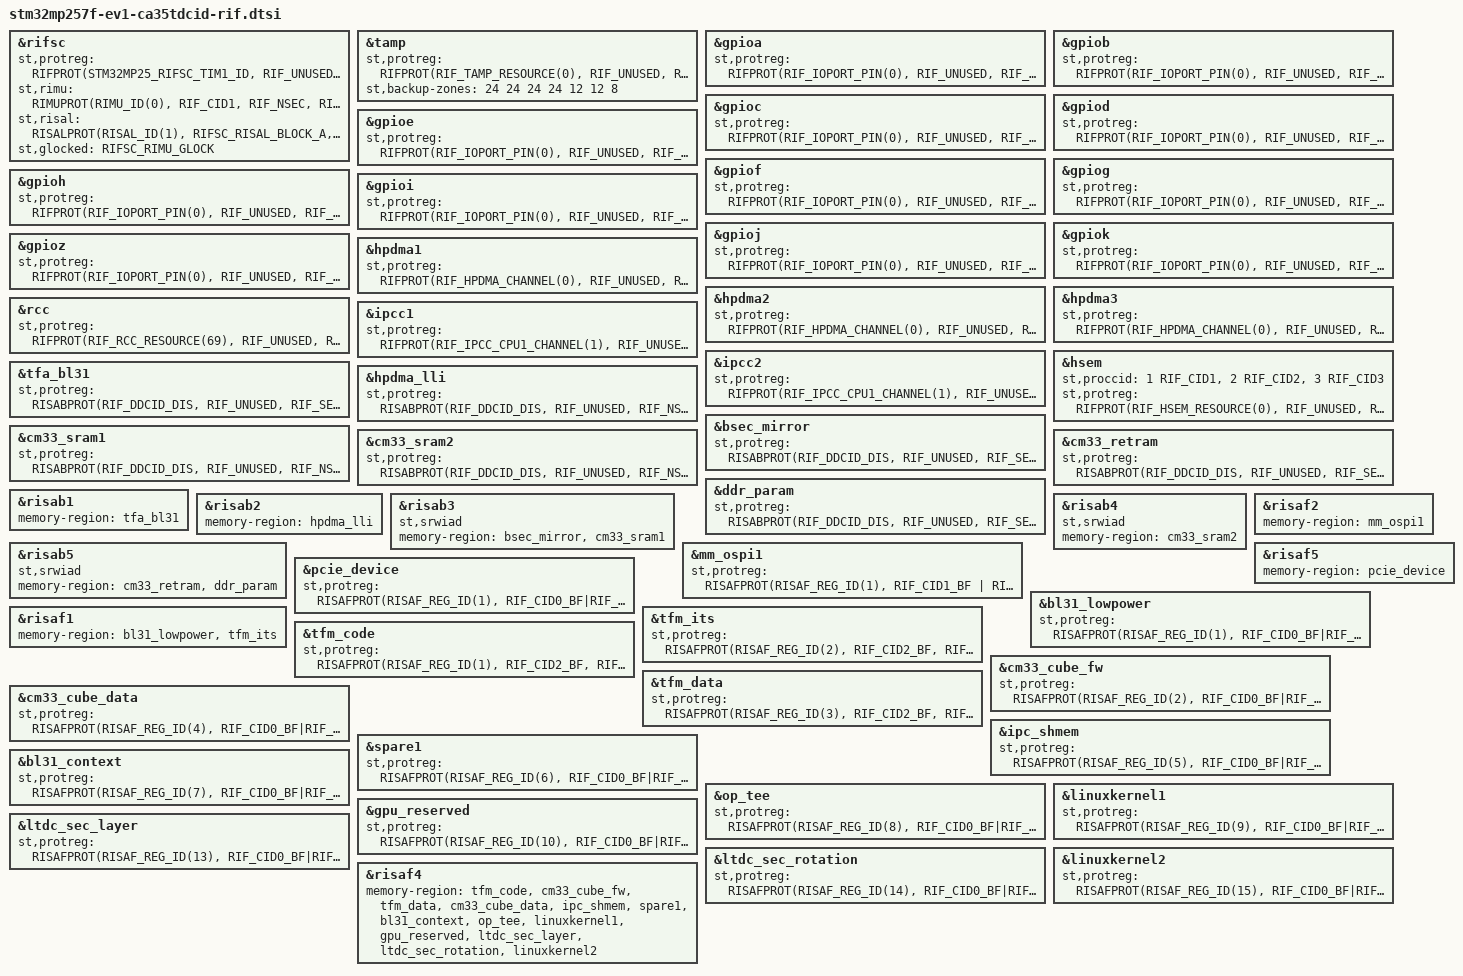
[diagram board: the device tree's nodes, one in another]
// SPDX-License-Identifier: (GPL-2.0-or-later OR BSD-3-Clause)
/*
 * Copyright (C) STMicroelectronics 2024 - All Rights Reserved
 */

/* Break alphabetical to group RIF configuration by feature to ease DT readability */

&rifsc {
	st,protreg = <
		RIFPROT(STM32MP25_RIFSC_TIM1_ID, RIF_UNUSED, RIF_UNLOCK, RIF_NSEC, RIF_NPRIV, RIF_UNUSED, RIF_SEM_DIS, RIF_CFDIS)
		RIFPROT(STM32MP25_RIFSC_TIM2_ID, RIF_UNUSED, RIF_UNLOCK, RIF_NSEC, RIF_NPRIV, RIF_UNUSED, RIF_SEM_DIS, RIF_CFDIS)
		RIFPROT(STM32MP25_RIFSC_TIM3_ID, RIF_UNUSED, RIF_UNLOCK, RIF_NSEC, RIF_NPRIV, RIF_UNUSED, RIF_SEM_DIS, RIF_CFDIS)
		RIFPROT(STM32MP25_RIFSC_TIM4_ID, RIF_UNUSED, RIF_UNLOCK, RIF_NSEC, RIF_NPRIV, RIF_UNUSED, RIF_SEM_DIS, RIF_CFDIS)
		RIFPROT(STM32MP25_RIFSC_TIM5_ID, RIF_UNUSED, RIF_UNLOCK, RIF_NSEC, RIF_NPRIV, RIF_UNUSED, RIF_SEM_DIS, RIF_CFDIS)
		RIFPROT(STM32MP25_RIFSC_TIM6_ID, RIF_UNUSED, RIF_UNLOCK, RIF_NSEC, RIF_NPRIV, RIF_UNUSED, RIF_SEM_DIS, RIF_CFDIS)
		RIFPROT(STM32MP25_RIFSC_TIM7_ID, RIF_UNUSED, RIF_UNLOCK, RIF_NSEC, RIF_NPRIV, RIF_UNUSED, RIF_SEM_DIS, RIF_CFDIS)
		RIFPROT(STM32MP25_RIFSC_TIM8_ID, RIF_UNUSED, RIF_UNLOCK, RIF_NSEC, RIF_NPRIV, RIF_UNUSED, RIF_SEM_DIS, RIF_CFDIS)
		RIFPROT(STM32MP25_RIFSC_TIM10_ID, RIF_UNUSED, RIF_UNLOCK, RIF_NSEC, RIF_NPRIV, RIF_UNUSED, RIF_SEM_DIS, RIF_CFDIS)
		RIFPROT(STM32MP25_RIFSC_TIM11_ID, RIF_UNUSED, RIF_UNLOCK, RIF_NSEC, RIF_NPRIV, RIF_UNUSED, RIF_SEM_DIS, RIF_CFDIS)
		RIFPROT(STM32MP25_RIFSC_TIM12_ID, RIF_UNUSED, RIF_UNLOCK, RIF_NSEC, RIF_NPRIV, RIF_UNUSED, RIF_SEM_DIS, RIF_CFDIS)
		RIFPROT(STM32MP25_RIFSC_TIM13_ID, RIF_UNUSED, RIF_UNLOCK, RIF_NSEC, RIF_NPRIV, RIF_UNUSED, RIF_SEM_DIS, RIF_CFDIS)
		RIFPROT(STM32MP25_RIFSC_TIM14_ID, RIF_UNUSED, RIF_UNLOCK, RIF_NSEC, RIF_NPRIV, RIF_UNUSED, RIF_SEM_DIS, RIF_CFDIS)
		RIFPROT(STM32MP25_RIFSC_TIM15_ID, RIF_UNUSED, RIF_UNLOCK, RIF_NSEC, RIF_NPRIV, RIF_UNUSED, RIF_SEM_DIS, RIF_CFDIS)
		RIFPROT(STM32MP25_RIFSC_TIM16_ID, RIF_UNUSED, RIF_UNLOCK, RIF_NSEC, RIF_NPRIV, RIF_UNUSED, RIF_SEM_DIS, RIF_CFDIS)
		RIFPROT(STM32MP25_RIFSC_TIM17_ID, RIF_UNUSED, RIF_UNLOCK, RIF_NSEC, RIF_NPRIV, RIF_UNUSED, RIF_SEM_DIS, RIF_CFDIS)
		RIFPROT(STM32MP25_RIFSC_TIM20_ID, RIF_UNUSED, RIF_UNLOCK, RIF_NSEC, RIF_NPRIV, RIF_UNUSED, RIF_SEM_DIS, RIF_CFDIS)
		RIFPROT(STM32MP25_RIFSC_LPTIM1_ID, RIF_UNUSED, RIF_UNLOCK, RIF_SEC, RIF_PRIV, RIF_CID1, RIF_SEM_DIS, RIF_CFEN)
		RIFPROT(STM32MP25_RIFSC_LPTIM2_ID, RIF_UNUSED, RIF_UNLOCK, RIF_NSEC, RIF_NPRIV, RIF_UNUSED, RIF_SEM_DIS, RIF_CFDIS)
		RIFPROT(STM32MP25_RIFSC_LPTIM3_ID, RIF_UNUSED, RIF_UNLOCK, RIF_NSEC, RIF_NPRIV, RIF_UNUSED, RIF_SEM_DIS, RIF_CFDIS)
		RIFPROT(STM32MP25_RIFSC_LPTIM4_ID, RIF_UNUSED, RIF_UNLOCK, RIF_NSEC, RIF_NPRIV, RIF_UNUSED, RIF_SEM_DIS, RIF_CFDIS)
		RIFPROT(STM32MP25_RIFSC_LPTIM5_ID, RIF_UNUSED, RIF_UNLOCK, RIF_NSEC, RIF_NPRIV, RIF_UNUSED, RIF_SEM_DIS, RIF_CFDIS)
		RIFPROT(STM32MP25_RIFSC_SPI1_ID, RIF_UNUSED, RIF_UNLOCK, RIF_NSEC, RIF_NPRIV, RIF_UNUSED, RIF_SEM_DIS, RIF_CFDIS)
		RIFPROT(STM32MP25_RIFSC_SPI2_ID, RIF_UNUSED, RIF_UNLOCK, RIF_NSEC, RIF_NPRIV, RIF_UNUSED, RIF_SEM_DIS, RIF_CFDIS)
		RIFPROT(STM32MP25_RIFSC_SPI3_ID, RIF_UNUSED, RIF_UNLOCK, RIF_NSEC, RIF_NPRIV, RIF_UNUSED, RIF_SEM_DIS, RIF_CFDIS)
		RIFPROT(STM32MP25_RIFSC_SPI4_ID, RIF_UNUSED, RIF_UNLOCK, RIF_NSEC, RIF_NPRIV, RIF_UNUSED, RIF_SEM_DIS, RIF_CFDIS)
		RIFPROT(STM32MP25_RIFSC_SPI5_ID, RIF_UNUSED, RIF_UNLOCK, RIF_NSEC, RIF_NPRIV, RIF_UNUSED, RIF_SEM_DIS, RIF_CFDIS)
		RIFPROT(STM32MP25_RIFSC_SPI6_ID, RIF_UNUSED, RIF_UNLOCK, RIF_NSEC, RIF_NPRIV, RIF_UNUSED, RIF_SEM_DIS, RIF_CFDIS)
		RIFPROT(STM32MP25_RIFSC_SPI7_ID, RIF_UNUSED, RIF_UNLOCK, RIF_NSEC, RIF_NPRIV, RIF_UNUSED, RIF_SEM_DIS, RIF_CFDIS)
		RIFPROT(STM32MP25_RIFSC_SPI8_ID, RIF_UNUSED, RIF_UNLOCK, RIF_NSEC, RIF_NPRIV, RIF_UNUSED, RIF_SEM_DIS, RIF_CFDIS)
		RIFPROT(STM32MP25_RIFSC_SPDIFRX_ID, RIF_UNUSED, RIF_UNLOCK, RIF_NSEC, RIF_NPRIV, RIF_UNUSED, RIF_SEM_DIS, RIF_CFDIS)
		RIFPROT(STM32MP25_RIFSC_USART1_ID, RIF_UNUSED, RIF_UNLOCK, RIF_NSEC, RIF_NPRIV, RIF_UNUSED, RIF_SEM_DIS, RIF_CFDIS)
		RIFPROT(STM32MP25_RIFSC_USART2_ID, RIF_UNUSED, RIF_UNLOCK, RIF_NSEC, RIF_NPRIV, RIF_UNUSED, RIF_SEM_DIS, RIF_CFDIS)
		RIFPROT(STM32MP25_RIFSC_USART3_ID, RIF_UNUSED, RIF_UNLOCK, RIF_NSEC, RIF_NPRIV, RIF_UNUSED, RIF_SEM_DIS, RIF_CFDIS)
		RIFPROT(STM32MP25_RIFSC_UART4_ID, RIF_UNUSED, RIF_UNLOCK, RIF_NSEC, RIF_NPRIV, RIF_UNUSED, RIF_SEM_DIS, RIF_CFDIS)
		RIFPROT(STM32MP25_RIFSC_UART5_ID, RIF_UNUSED, RIF_UNLOCK, RIF_NSEC, RIF_NPRIV, RIF_UNUSED, RIF_SEM_DIS, RIF_CFDIS)
		RIFPROT(STM32MP25_RIFSC_USART6_ID, RIF_UNUSED, RIF_UNLOCK, RIF_NSEC, RIF_NPRIV, RIF_UNUSED, RIF_SEM_DIS, RIF_CFDIS)
		RIFPROT(STM32MP25_RIFSC_UART7_ID, RIF_UNUSED, RIF_UNLOCK, RIF_NSEC, RIF_NPRIV, RIF_UNUSED, RIF_SEM_DIS, RIF_CFDIS)
		RIFPROT(STM32MP25_RIFSC_UART8_ID, RIF_UNUSED, RIF_UNLOCK, RIF_NSEC, RIF_NPRIV, RIF_UNUSED, RIF_SEM_DIS, RIF_CFDIS)
		RIFPROT(STM32MP25_RIFSC_UART9_ID, RIF_UNUSED, RIF_UNLOCK, RIF_NSEC, RIF_NPRIV, RIF_UNUSED, RIF_SEM_DIS, RIF_CFDIS)
		RIFPROT(STM32MP25_RIFSC_LPUART1_ID, RIF_UNUSED, RIF_UNLOCK, RIF_NSEC, RIF_NPRIV, RIF_UNUSED, RIF_SEM_DIS, RIF_CFDIS)
		RIFPROT(STM32MP25_RIFSC_I2C1_ID, RIF_UNUSED, RIF_UNLOCK, RIF_NSEC, RIF_NPRIV, RIF_UNUSED, RIF_SEM_DIS, RIF_CFDIS)
		RIFPROT(STM32MP25_RIFSC_I2C2_ID, RIF_UNUSED, RIF_UNLOCK, RIF_NSEC, RIF_NPRIV, RIF_UNUSED, RIF_SEM_DIS, RIF_CFDIS)
		RIFPROT(STM32MP25_RIFSC_I2C3_ID, RIF_UNUSED, RIF_UNLOCK, RIF_NSEC, RIF_NPRIV, RIF_UNUSED, RIF_SEM_DIS, RIF_CFDIS)
		RIFPROT(STM32MP25_RIFSC_I2C4_ID, RIF_UNUSED, RIF_UNLOCK, RIF_NSEC, RIF_NPRIV, RIF_UNUSED, RIF_SEM_DIS, RIF_CFDIS)
		RIFPROT(STM32MP25_RIFSC_I2C5_ID, RIF_UNUSED, RIF_UNLOCK, RIF_NSEC, RIF_NPRIV, RIF_UNUSED, RIF_SEM_DIS, RIF_CFDIS)
		RIFPROT(STM32MP25_RIFSC_I2C6_ID, RIF_UNUSED, RIF_UNLOCK, RIF_NSEC, RIF_NPRIV, RIF_UNUSED, RIF_SEM_DIS, RIF_CFDIS)
		RIFPROT(STM32MP25_RIFSC_I2C7_ID, RIF_UNUSED, RIF_UNLOCK, RIF_SEC, RIF_PRIV, RIF_CID1, RIF_SEM_DIS, RIF_CFEN)
		RIFPROT(STM32MP25_RIFSC_I2C8_ID, RIF_UNUSED, RIF_UNLOCK, RIF_NSEC, RIF_NPRIV, RIF_UNUSED, RIF_SEM_DIS, RIF_CFDIS)
		RIFPROT(STM32MP25_RIFSC_SAI1_ID, RIF_UNUSED, RIF_UNLOCK, RIF_NSEC, RIF_NPRIV, RIF_UNUSED, RIF_SEM_DIS, RIF_CFDIS)
		RIFPROT(STM32MP25_RIFSC_SAI2_ID, RIF_UNUSED, RIF_UNLOCK, RIF_NSEC, RIF_NPRIV, RIF_UNUSED, RIF_SEM_DIS, RIF_CFDIS)
		RIFPROT(STM32MP25_RIFSC_SAI3_ID, RIF_UNUSED, RIF_UNLOCK, RIF_NSEC, RIF_NPRIV, RIF_UNUSED, RIF_SEM_DIS, RIF_CFDIS)
		RIFPROT(STM32MP25_RIFSC_SAI4_ID, RIF_UNUSED, RIF_UNLOCK, RIF_NSEC, RIF_NPRIV, RIF_UNUSED, RIF_SEM_DIS, RIF_CFDIS)
		RIFPROT(STM32MP25_RIFSC_MDF1_ID, RIF_UNUSED, RIF_UNLOCK, RIF_NSEC, RIF_NPRIV, RIF_UNUSED, RIF_SEM_DIS, RIF_CFDIS)
		RIFPROT(STM32MP25_RIFSC_ADF1_ID, RIF_UNUSED, RIF_UNLOCK, RIF_NSEC, RIF_NPRIV, RIF_UNUSED, RIF_SEM_DIS, RIF_CFDIS)
		RIFPROT(STM32MP25_RIFSC_FDCAN_ID, RIF_UNUSED, RIF_UNLOCK, RIF_NSEC, RIF_NPRIV, RIF_UNUSED, RIF_SEM_DIS, RIF_CFDIS)
		RIFPROT(STM32MP25_RIFSC_HDP_ID, RIF_UNUSED, RIF_UNLOCK, RIF_NSEC, RIF_NPRIV, RIF_UNUSED, RIF_SEM_DIS, RIF_CFDIS)
		RIFPROT(STM32MP25_RIFSC_ADC12_ID, RIF_UNUSED, RIF_UNLOCK, RIF_NSEC, RIF_NPRIV, RIF_UNUSED, RIF_SEM_DIS, RIF_CFDIS)
		RIFPROT(STM32MP25_RIFSC_ADC3_ID, RIF_UNUSED, RIF_UNLOCK, RIF_NSEC, RIF_NPRIV, RIF_UNUSED, RIF_SEM_DIS, RIF_CFDIS)
		RIFPROT(STM32MP25_RIFSC_ETH1_ID, RIF_UNUSED, RIF_UNLOCK, RIF_NSEC, RIF_NPRIV, RIF_UNUSED, RIF_SEM_DIS, RIF_CFDIS)
		RIFPROT(STM32MP25_RIFSC_ETH2_ID, RIF_UNUSED, RIF_UNLOCK, RIF_NSEC, RIF_NPRIV, RIF_UNUSED, RIF_SEM_DIS, RIF_CFDIS)
		RIFPROT(STM32MP25_RIFSC_ETHSW_DEIP_ID, RIF_UNUSED, RIF_UNLOCK, RIF_NSEC, RIF_NPRIV, RIF_UNUSED, RIF_SEM_DIS, RIF_CFDIS)
		RIFPROT(STM32MP25_RIFSC_ETHSW_ACM_MSGBUF_ID, RIF_UNUSED, RIF_UNLOCK, RIF_NSEC, RIF_NPRIV, RIF_UNUSED, RIF_SEM_DIS, RIF_CFDIS)
		RIFPROT(STM32MP25_RIFSC_ETHSW_ACM_CFG_ID, RIF_UNUSED, RIF_UNLOCK, RIF_NSEC, RIF_NPRIV, RIF_UNUSED, RIF_SEM_DIS, RIF_CFDIS)
		RIFPROT(STM32MP25_RIFSC_USBH_ID, RIF_UNUSED, RIF_UNLOCK, RIF_NSEC, RIF_NPRIV, RIF_UNUSED, RIF_SEM_DIS, RIF_CFDIS)
		RIFPROT(STM32MP25_RIFSC_USB3DR_ID, RIF_UNUSED, RIF_UNLOCK, RIF_NSEC, RIF_NPRIV, RIF_UNUSED, RIF_SEM_DIS, RIF_CFDIS)
		RIFPROT(STM32MP25_RIFSC_COMBOPHY_ID, RIF_UNUSED, RIF_UNLOCK, RIF_NSEC, RIF_NPRIV, RIF_UNUSED, RIF_SEM_DIS, RIF_CFDIS)
		RIFPROT(STM32MP25_RIFSC_PCIE_ID, RIF_UNUSED, RIF_UNLOCK, RIF_NSEC, RIF_NPRIV, RIF_UNUSED, RIF_SEM_DIS, RIF_CFDIS)
		RIFPROT(STM32MP25_RIFSC_UCPD1_ID, RIF_UNUSED, RIF_UNLOCK, RIF_NSEC, RIF_NPRIV, RIF_UNUSED, RIF_SEM_DIS, RIF_CFDIS)
		RIFPROT(STM32MP25_RIFSC_STGEN_ID, RIF_UNUSED, RIF_LOCK, RIF_SEC, RIF_PRIV, RIF_CID1, RIF_SEM_DIS, RIF_CFEN)
		RIFPROT(STM32MP25_RIFSC_SDMMC1_ID, RIF_UNUSED, RIF_UNLOCK, RIF_NSEC, RIF_NPRIV, RIF_UNUSED, RIF_SEM_DIS, RIF_CFDIS)
		RIFPROT(STM32MP25_RIFSC_SDMMC2_ID, RIF_UNUSED, RIF_UNLOCK, RIF_NSEC, RIF_NPRIV, RIF_UNUSED, RIF_SEM_DIS, RIF_CFDIS)
		RIFPROT(STM32MP25_RIFSC_SDMMC3_ID, RIF_UNUSED, RIF_UNLOCK, RIF_NSEC, RIF_NPRIV, RIF_UNUSED, RIF_SEM_DIS, RIF_CFDIS)
		RIFPROT(STM32MP25_RIFSC_GPU_ID, RIF_UNUSED, RIF_UNLOCK, RIF_NSEC, RIF_NPRIV, RIF_UNUSED, RIF_SEM_DIS, RIF_CFDIS)
		RIFPROT(STM32MP25_RIFSC_LTDC_CMN_ID, RIF_UNUSED, RIF_UNLOCK, RIF_NSEC, RIF_NPRIV, RIF_UNUSED, RIF_SEM_DIS, RIF_CFDIS)
		RIFPROT(STM32MP25_RIFSC_LTDC_L0L1_ID, RIF_UNUSED, RIF_UNLOCK, RIF_NSEC, RIF_NPRIV, RIF_UNUSED, RIF_SEM_DIS, RIF_CFDIS)
		RIFPROT(STM32MP25_RIFSC_LTDC_L2_ID, RIF_UNUSED, RIF_UNLOCK, RIF_NSEC, RIF_NPRIV, RIF_UNUSED, RIF_SEM_DIS, RIF_CFDIS)
		RIFPROT(STM32MP25_RIFSC_LTDC_ROT_ID, RIF_UNUSED, RIF_UNLOCK, RIF_NSEC, RIF_NPRIV, RIF_UNUSED, RIF_SEM_DIS, RIF_CFDIS)
		RIFPROT(STM32MP25_RIFSC_DSI_CMN_ID, RIF_UNUSED, RIF_UNLOCK, RIF_NSEC, RIF_NPRIV, RIF_UNUSED, RIF_SEM_DIS, RIF_CFDIS)
		RIFPROT(STM32MP25_RIFSC_DSI_TRIG_ID, RIF_UNUSED, RIF_UNLOCK, RIF_NSEC, RIF_NPRIV, RIF_UNUSED, RIF_SEM_DIS, RIF_CFDIS)
		RIFPROT(STM32MP25_RIFSC_DSI_RDFIFO_ID, RIF_UNUSED, RIF_UNLOCK, RIF_NSEC, RIF_NPRIV, RIF_UNUSED, RIF_SEM_DIS, RIF_CFDIS)
		RIFPROT(STM32MP25_RIFSC_LVDS_ID, RIF_UNUSED, RIF_UNLOCK, RIF_NSEC, RIF_NPRIV, RIF_UNUSED, RIF_SEM_DIS, RIF_CFDIS)
		RIFPROT(STM32MP25_RIFSC_CSI_ID, RIF_UNUSED, RIF_UNLOCK, RIF_NSEC, RIF_NPRIV, RIF_UNUSED, RIF_SEM_DIS, RIF_CFDIS)
		RIFPROT(STM32MP25_RIFSC_DCMIPP_ID, RIF_UNUSED, RIF_UNLOCK, RIF_NSEC, RIF_NPRIV, RIF_UNUSED, RIF_SEM_DIS, RIF_CFDIS)
		RIFPROT(STM32MP25_RIFSC_DCMI_PSSI_ID, RIF_UNUSED, RIF_UNLOCK, RIF_NSEC, RIF_NPRIV, RIF_UNUSED, RIF_SEM_DIS, RIF_CFDIS)
		RIFPROT(STM32MP25_RIFSC_VDEC_ID, RIF_UNUSED, RIF_UNLOCK, RIF_NSEC, RIF_NPRIV, RIF_UNUSED, RIF_SEM_DIS, RIF_CFDIS)
		RIFPROT(STM32MP25_RIFSC_VENC_ID, RIF_UNUSED, RIF_UNLOCK, RIF_NSEC, RIF_NPRIV, RIF_UNUSED, RIF_SEM_DIS, RIF_CFDIS)
		RIFPROT(STM32MP25_RIFSC_RNG_ID, RIF_UNUSED, RIF_LOCK, RIF_SEC, RIF_PRIV, RIF_CID1, RIF_SEM_DIS, RIF_CFEN)
		RIFPROT(STM32MP25_RIFSC_PKA_ID, RIF_UNUSED, RIF_LOCK, RIF_SEC, RIF_PRIV, RIF_CID1, RIF_SEM_DIS, RIF_CFEN)
		RIFPROT(STM32MP25_RIFSC_SAES_ID, RIF_UNUSED, RIF_LOCK, RIF_SEC, RIF_PRIV, RIF_CID1, RIF_SEM_DIS, RIF_CFEN)
		RIFPROT(STM32MP25_RIFSC_HASH_ID, RIF_UNUSED, RIF_LOCK, RIF_SEC, RIF_PRIV, RIF_CID1, RIF_SEM_DIS, RIF_CFEN)
		RIFPROT(STM32MP25_RIFSC_CRYP1_ID, RIF_UNUSED, RIF_UNLOCK, RIF_NSEC, RIF_NPRIV, RIF_UNUSED, RIF_SEM_DIS, RIF_CFDIS)
		RIFPROT(STM32MP25_RIFSC_CRYP2_ID, RIF_UNUSED, RIF_UNLOCK, RIF_SEC, RIF_PRIV, RIF_CID2, RIF_SEM_DIS, RIF_CFEN)
		RIFPROT(STM32MP25_RIFSC_IWDG1_ID, RIF_UNUSED, RIF_LOCK, RIF_SEC, RIF_PRIV, RIF_CID1, RIF_SEM_DIS, RIF_CFEN)
		RIFPROT(STM32MP25_RIFSC_IWDG2_ID, RIF_UNUSED, RIF_UNLOCK, RIF_NSEC, RIF_NPRIV, RIF_UNUSED, RIF_SEM_DIS, RIF_CFDIS)
		RIFPROT(STM32MP25_RIFSC_IWDG3_ID, RIF_UNUSED, RIF_UNLOCK, RIF_SEC, RIF_PRIV, RIF_CID2, RIF_SEM_DIS, RIF_CFEN)
		RIFPROT(STM32MP25_RIFSC_IWDG4_ID, RIF_UNUSED, RIF_UNLOCK, RIF_NSEC, RIF_NPRIV, RIF_UNUSED, RIF_SEM_DIS, RIF_CFDIS)
		RIFPROT(STM32MP25_RIFSC_IWDG5_ID, RIF_UNUSED, RIF_UNLOCK, RIF_NSEC, RIF_NPRIV, RIF_UNUSED, RIF_SEM_DIS, RIF_CFDIS)
		RIFPROT(STM32MP25_RIFSC_WWDG1_ID, RIF_UNUSED, RIF_UNLOCK, RIF_NSEC, RIF_NPRIV, RIF_UNUSED, RIF_SEM_DIS, RIF_CFDIS)
		RIFPROT(STM32MP25_RIFSC_WWDG2_ID, RIF_UNUSED, RIF_UNLOCK, RIF_NSEC, RIF_NPRIV, RIF_UNUSED, RIF_SEM_DIS, RIF_CFDIS)
		RIFPROT(STM32MP25_RIFSC_VREFBUF_ID, RIF_UNUSED, RIF_UNLOCK, RIF_SEC, RIF_PRIV, RIF_CID1, RIF_SEM_DIS, RIF_CFEN)
		RIFPROT(STM32MP25_RIFSC_DTS_ID, RIF_UNUSED, RIF_UNLOCK, RIF_NSEC, RIF_NPRIV, RIF_UNUSED, RIF_SEM_DIS, RIF_CFDIS)
		RIFPROT(STM32MP25_RIFSC_RAMCFG_ID, RIF_UNUSED, RIF_UNLOCK, RIF_SEC, RIF_PRIV, RIF_CID1, RIF_SEM_DIS, RIF_CFEN)
		RIFPROT(STM32MP25_RIFSC_CRC_ID, RIF_UNUSED, RIF_UNLOCK, RIF_NSEC, RIF_NPRIV, RIF_UNUSED, RIF_SEM_DIS, RIF_CFDIS)
		RIFPROT(STM32MP25_RIFSC_SERC_ID, RIF_UNUSED, RIF_UNLOCK, RIF_SEC, RIF_PRIV, RIF_CID1, RIF_SEM_DIS, RIF_CFEN)
		RIFPROT(STM32MP25_RIFSC_GICV2M_ID, RIF_UNUSED, RIF_UNLOCK, RIF_NSEC, RIF_NPRIV, RIF_UNUSED, RIF_SEM_DIS, RIF_CFDIS)
		RIFPROT(STM32MP25_RIFSC_I3C1_ID, RIF_UNUSED, RIF_UNLOCK, RIF_NSEC, RIF_NPRIV, RIF_UNUSED, RIF_SEM_DIS, RIF_CFDIS)
		RIFPROT(STM32MP25_RIFSC_I3C2_ID, RIF_UNUSED, RIF_UNLOCK, RIF_NSEC, RIF_NPRIV, RIF_UNUSED, RIF_SEM_DIS, RIF_CFDIS)
		RIFPROT(STM32MP25_RIFSC_I3C3_ID, RIF_UNUSED, RIF_UNLOCK, RIF_NSEC, RIF_NPRIV, RIF_UNUSED, RIF_SEM_DIS, RIF_CFDIS)
		RIFPROT(STM32MP25_RIFSC_I3C4_ID, RIF_UNUSED, RIF_UNLOCK, RIF_NSEC, RIF_NPRIV, RIF_UNUSED, RIF_SEM_DIS, RIF_CFDIS)
		RIFPROT(STM32MP25_RIFSC_ICACHE_DCACHE_ID, RIF_UNUSED, RIF_UNLOCK, RIF_NSEC, RIF_NPRIV, RIF_UNUSED, RIF_SEM_DIS, RIF_CFDIS)
	>;
	st,rimu = <
		RIMUPROT(RIMU_ID(0), RIF_CID1, RIF_NSEC, RIF_PRIV, RIF_CIDSEL_M)
		RIMUPROT(RIMU_ID(1), RIF_UNUSED, RIF_NSEC, RIF_PRIV, RIF_CIDSEL_P)
		RIMUPROT(RIMU_ID(2), RIF_UNUSED, RIF_NSEC, RIF_PRIV, RIF_CIDSEL_P)
		RIMUPROT(RIMU_ID(3), RIF_UNUSED, RIF_NSEC, RIF_PRIV, RIF_CIDSEL_P)
		RIMUPROT(RIMU_ID(4), RIF_UNUSED, RIF_NSEC, RIF_PRIV, RIF_CIDSEL_P)
		RIMUPROT(RIMU_ID(5), RIF_UNUSED, RIF_NSEC, RIF_PRIV, RIF_CIDSEL_P)
		RIMUPROT(RIMU_ID(6), RIF_UNUSED, RIF_NSEC, RIF_PRIV, RIF_CIDSEL_P)
		RIMUPROT(RIMU_ID(7), RIF_UNUSED, RIF_NSEC, RIF_PRIV, RIF_CIDSEL_P)
		RIMUPROT(RIMU_ID(8), RIF_UNUSED, RIF_NSEC, RIF_PRIV, RIF_CIDSEL_P)
		RIMUPROT(RIMU_ID(9), RIF_UNUSED, RIF_NSEC, RIF_PRIV, RIF_CIDSEL_P)
		RIMUPROT(RIMU_ID(10), RIF_UNUSED, RIF_NSEC, RIF_PRIV, RIF_CIDSEL_P)
		RIMUPROT(RIMU_ID(11), RIF_CID0, RIF_NSEC, RIF_PRIV, RIF_CIDSEL_M)
		RIMUPROT(RIMU_ID(12), RIF_CID0, RIF_NSEC, RIF_PRIV, RIF_CIDSEL_M)
		RIMUPROT(RIMU_ID(13), RIF_CID0, RIF_NSEC, RIF_PRIV, RIF_CIDSEL_M)
		RIMUPROT(RIMU_ID(14), RIF_UNUSED, RIF_NSEC, RIF_PRIV, RIF_CIDSEL_P)
		RIMUPROT(RIMU_ID(15), RIF_UNUSED, RIF_NSEC, RIF_PRIV, RIF_CIDSEL_P)
	>;
	st,risal = <
		RISALPROT(RISAL_ID(1), RIFSC_RISAL_BLOCK_A, RIF_CID1, RIF_UNLOCK, RIF_NSEC, RIF_NPRIV, RIFSC_RISAL_SREN)
		RISALPROT(RISAL_ID(2), RIFSC_RISAL_BLOCK_A, RIF_CID1, RIF_UNLOCK, RIF_NSEC, RIF_NPRIV, RIFSC_RISAL_SREN)
		RISALPROT(RISAL_ID(3), RIFSC_RISAL_BLOCK_A, RIF_CID1, RIF_UNLOCK, RIF_NSEC, RIF_NPRIV, RIFSC_RISAL_SREN)
		RISALPROT(RISAL_ID(1), RIFSC_RISAL_BLOCK_B, RIF_CID3, RIF_UNLOCK, RIF_NSEC, RIF_NPRIV, RIFSC_RISAL_SREN)
		RISALPROT(RISAL_ID(2), RIFSC_RISAL_BLOCK_B, RIF_CID3, RIF_UNLOCK, RIF_NSEC, RIF_NPRIV, RIFSC_RISAL_SREN)
		RISALPROT(RISAL_ID(3), RIFSC_RISAL_BLOCK_B, RIF_CID3, RIF_UNLOCK, RIF_NSEC, RIF_NPRIV, RIFSC_RISAL_SREN)
	>;
	st,glocked = <RIFSC_RIMU_GLOCK>;
};

&tamp {
	st,protreg = <
		RIFPROT(RIF_TAMP_RESOURCE(0), RIF_UNUSED, RIF_UNLOCK, RIF_SEC, RIF_PRIV, RIF_CID1, RIF_SEM_DIS, RIF_CFEN)
		RIFPROT(RIF_TAMP_RESOURCE(1), RIF_UNUSED, RIF_UNLOCK, RIF_SEC, RIF_PRIV, RIF_CID1, RIF_SEM_DIS, RIF_CFEN)
		RIFPROT(RIF_TAMP_RESOURCE(2), RIF_UNUSED, RIF_UNLOCK, RIF_SEC, RIF_PRIV, RIF_CID2, RIF_SEM_DIS, RIF_CFEN)
	>;
	st,backup-zones = <24 24 24 24 12 12 8>;
};

&gpioa {
	st,protreg = <
		RIFPROT(RIF_IOPORT_PIN(0), RIF_UNUSED, RIF_UNLOCK, RIF_SEC, RIF_PRIV, RIF_CID1, RIF_SEM_DIS, RIF_CFEN)
		RIFPROT(RIF_IOPORT_PIN(1), RIF_UNUSED, RIF_UNLOCK, RIF_NSEC, RIF_NPRIV, RIF_UNUSED, RIF_SEM_DIS, RIF_CFDIS)
		RIFPROT(RIF_IOPORT_PIN(2), RIF_UNUSED, RIF_UNLOCK, RIF_NSEC, RIF_NPRIV, RIF_UNUSED, RIF_SEM_DIS, RIF_CFDIS)
		RIFPROT(RIF_IOPORT_PIN(3), RIF_UNUSED, RIF_UNLOCK, RIF_NSEC, RIF_NPRIV, RIF_UNUSED, RIF_SEM_DIS, RIF_CFDIS)
		RIFPROT(RIF_IOPORT_PIN(4), RIF_UNUSED, RIF_UNLOCK, RIF_NSEC, RIF_NPRIV, RIF_UNUSED, RIF_SEM_DIS, RIF_CFDIS)
		RIFPROT(RIF_IOPORT_PIN(5), RIF_UNUSED, RIF_UNLOCK, RIF_NSEC, RIF_NPRIV, RIF_UNUSED, RIF_SEM_DIS, RIF_CFDIS)
		RIFPROT(RIF_IOPORT_PIN(6), RIF_UNUSED, RIF_UNLOCK, RIF_NSEC, RIF_NPRIV, RIF_UNUSED, RIF_SEM_DIS, RIF_CFDIS)
		RIFPROT(RIF_IOPORT_PIN(7), RIF_UNUSED, RIF_UNLOCK, RIF_NSEC, RIF_NPRIV, RIF_UNUSED, RIF_SEM_DIS, RIF_CFDIS)
		RIFPROT(RIF_IOPORT_PIN(8), RIF_UNUSED, RIF_UNLOCK, RIF_NSEC, RIF_NPRIV, RIF_UNUSED, RIF_SEM_DIS, RIF_CFDIS)
		RIFPROT(RIF_IOPORT_PIN(9), RIF_UNUSED, RIF_UNLOCK, RIF_NSEC, RIF_NPRIV, RIF_UNUSED, RIF_SEM_DIS, RIF_CFDIS)
		RIFPROT(RIF_IOPORT_PIN(10), RIF_UNUSED, RIF_UNLOCK, RIF_NSEC, RIF_NPRIV, RIF_UNUSED, RIF_SEM_DIS, RIF_CFDIS)
		RIFPROT(RIF_IOPORT_PIN(11), RIF_UNUSED, RIF_UNLOCK, RIF_NSEC, RIF_NPRIV, RIF_UNUSED, RIF_SEM_DIS, RIF_CFDIS)
		RIFPROT(RIF_IOPORT_PIN(12), RIF_UNUSED, RIF_UNLOCK, RIF_NSEC, RIF_NPRIV, RIF_UNUSED, RIF_SEM_DIS, RIF_CFDIS)
		RIFPROT(RIF_IOPORT_PIN(13), RIF_UNUSED, RIF_UNLOCK, RIF_NSEC, RIF_NPRIV, RIF_UNUSED, RIF_SEM_DIS, RIF_CFDIS)
		RIFPROT(RIF_IOPORT_PIN(14), RIF_UNUSED, RIF_UNLOCK, RIF_NSEC, RIF_NPRIV, RIF_UNUSED, RIF_SEM_DIS, RIF_CFDIS)
		RIFPROT(RIF_IOPORT_PIN(15), RIF_UNUSED, RIF_UNLOCK, RIF_NSEC, RIF_NPRIV, RIF_UNUSED, RIF_SEM_DIS, RIF_CFDIS)
	>;
};

&gpiob {
	st,protreg = <
		RIFPROT(RIF_IOPORT_PIN(0), RIF_UNUSED, RIF_UNLOCK, RIF_NSEC, RIF_NPRIV, RIF_UNUSED, RIF_SEM_DIS, RIF_CFDIS)
		RIFPROT(RIF_IOPORT_PIN(1), RIF_UNUSED, RIF_UNLOCK, RIF_NSEC, RIF_NPRIV, RIF_UNUSED, RIF_SEM_DIS, RIF_CFDIS)
		RIFPROT(RIF_IOPORT_PIN(2), RIF_UNUSED, RIF_UNLOCK, RIF_NSEC, RIF_NPRIV, RIF_UNUSED, RIF_SEM_DIS, RIF_CFDIS)
		RIFPROT(RIF_IOPORT_PIN(3), RIF_UNUSED, RIF_UNLOCK, RIF_NSEC, RIF_NPRIV, RIF_UNUSED, RIF_SEM_DIS, RIF_CFDIS)
		RIFPROT(RIF_IOPORT_PIN(4), RIF_UNUSED, RIF_UNLOCK, RIF_NSEC, RIF_NPRIV, RIF_UNUSED, RIF_SEM_DIS, RIF_CFDIS)
		RIFPROT(RIF_IOPORT_PIN(5), RIF_UNUSED, RIF_UNLOCK, RIF_NSEC, RIF_NPRIV, RIF_UNUSED, RIF_SEM_DIS, RIF_CFDIS)
		RIFPROT(RIF_IOPORT_PIN(6), RIF_UNUSED, RIF_UNLOCK, RIF_NSEC, RIF_NPRIV, RIF_UNUSED, RIF_SEM_DIS, RIF_CFDIS)
		RIFPROT(RIF_IOPORT_PIN(7), RIF_UNUSED, RIF_UNLOCK, RIF_NSEC, RIF_NPRIV, RIF_UNUSED, RIF_SEM_DIS, RIF_CFDIS)
		RIFPROT(RIF_IOPORT_PIN(8), RIF_UNUSED, RIF_UNLOCK, RIF_NSEC, RIF_NPRIV, RIF_UNUSED, RIF_SEM_DIS, RIF_CFDIS)
		RIFPROT(RIF_IOPORT_PIN(9), RIF_UNUSED, RIF_UNLOCK, RIF_NSEC, RIF_NPRIV, RIF_UNUSED, RIF_SEM_DIS, RIF_CFDIS)
		RIFPROT(RIF_IOPORT_PIN(10), RIF_UNUSED, RIF_UNLOCK, RIF_NSEC, RIF_NPRIV, RIF_UNUSED, RIF_SEM_DIS, RIF_CFDIS)
		RIFPROT(RIF_IOPORT_PIN(11), RIF_UNUSED, RIF_UNLOCK, RIF_NSEC, RIF_NPRIV, RIF_UNUSED, RIF_SEM_DIS, RIF_CFDIS)
		RIFPROT(RIF_IOPORT_PIN(12), RIF_UNUSED, RIF_UNLOCK, RIF_NSEC, RIF_NPRIV, RIF_UNUSED, RIF_SEM_DIS, RIF_CFDIS)
		RIFPROT(RIF_IOPORT_PIN(13), RIF_UNUSED, RIF_UNLOCK, RIF_NSEC, RIF_NPRIV, RIF_UNUSED, RIF_SEM_DIS, RIF_CFDIS)
		RIFPROT(RIF_IOPORT_PIN(14), RIF_UNUSED, RIF_UNLOCK, RIF_NSEC, RIF_NPRIV, RIF_UNUSED, RIF_SEM_DIS, RIF_CFDIS)
		RIFPROT(RIF_IOPORT_PIN(15), RIF_UNUSED, RIF_UNLOCK, RIF_NSEC, RIF_NPRIV, RIF_UNUSED, RIF_SEM_DIS, RIF_CFDIS)
	>;
};

&gpioc {
	st,protreg = <
		RIFPROT(RIF_IOPORT_PIN(0), RIF_UNUSED, RIF_UNLOCK, RIF_NSEC, RIF_NPRIV, RIF_UNUSED, RIF_SEM_DIS, RIF_CFDIS)
		RIFPROT(RIF_IOPORT_PIN(1), RIF_UNUSED, RIF_UNLOCK, RIF_NSEC, RIF_NPRIV, RIF_UNUSED, RIF_SEM_DIS, RIF_CFDIS)
		RIFPROT(RIF_IOPORT_PIN(2), RIF_UNUSED, RIF_UNLOCK, RIF_NSEC, RIF_NPRIV, RIF_UNUSED, RIF_SEM_DIS, RIF_CFDIS)
		RIFPROT(RIF_IOPORT_PIN(3), RIF_UNUSED, RIF_UNLOCK, RIF_NSEC, RIF_NPRIV, RIF_UNUSED, RIF_SEM_DIS, RIF_CFDIS)
		RIFPROT(RIF_IOPORT_PIN(4), RIF_UNUSED, RIF_UNLOCK, RIF_NSEC, RIF_NPRIV, RIF_UNUSED, RIF_SEM_DIS, RIF_CFDIS)
		RIFPROT(RIF_IOPORT_PIN(5), RIF_UNUSED, RIF_UNLOCK, RIF_NSEC, RIF_NPRIV, RIF_UNUSED, RIF_SEM_DIS, RIF_CFDIS)
		RIFPROT(RIF_IOPORT_PIN(6), RIF_UNUSED, RIF_UNLOCK, RIF_NSEC, RIF_NPRIV, RIF_UNUSED, RIF_SEM_DIS, RIF_CFDIS)
		RIFPROT(RIF_IOPORT_PIN(7), RIF_UNUSED, RIF_UNLOCK, RIF_NSEC, RIF_NPRIV, RIF_UNUSED, RIF_SEM_DIS, RIF_CFDIS)
		RIFPROT(RIF_IOPORT_PIN(8), RIF_UNUSED, RIF_UNLOCK, RIF_NSEC, RIF_NPRIV, RIF_UNUSED, RIF_SEM_DIS, RIF_CFDIS)
		RIFPROT(RIF_IOPORT_PIN(9), RIF_UNUSED, RIF_UNLOCK, RIF_NSEC, RIF_NPRIV, RIF_UNUSED, RIF_SEM_DIS, RIF_CFDIS)
		RIFPROT(RIF_IOPORT_PIN(10), RIF_UNUSED, RIF_UNLOCK, RIF_NSEC, RIF_NPRIV, RIF_UNUSED, RIF_SEM_DIS, RIF_CFDIS)
		RIFPROT(RIF_IOPORT_PIN(11), RIF_UNUSED, RIF_UNLOCK, RIF_NSEC, RIF_NPRIV, RIF_UNUSED, RIF_SEM_DIS, RIF_CFDIS)
		RIFPROT(RIF_IOPORT_PIN(12), RIF_UNUSED, RIF_UNLOCK, RIF_NSEC, RIF_NPRIV, RIF_UNUSED, RIF_SEM_DIS, RIF_CFDIS)
		RIFPROT(RIF_IOPORT_PIN(13), RIF_UNUSED, RIF_UNLOCK, RIF_NSEC, RIF_NPRIV, RIF_UNUSED, RIF_SEM_DIS, RIF_CFDIS)
	>;
};

&gpiod {
	st,protreg = <
		RIFPROT(RIF_IOPORT_PIN(0), RIF_UNUSED, RIF_UNLOCK, RIF_NSEC, RIF_NPRIV, RIF_UNUSED, RIF_SEM_DIS, RIF_CFDIS)
		RIFPROT(RIF_IOPORT_PIN(1), RIF_UNUSED, RIF_UNLOCK, RIF_NSEC, RIF_NPRIV, RIF_UNUSED, RIF_SEM_DIS, RIF_CFDIS)
		RIFPROT(RIF_IOPORT_PIN(2), RIF_UNUSED, RIF_UNLOCK, RIF_NSEC, RIF_NPRIV, RIF_UNUSED, RIF_SEM_DIS, RIF_CFDIS)
		RIFPROT(RIF_IOPORT_PIN(3), RIF_UNUSED, RIF_UNLOCK, RIF_NSEC, RIF_NPRIV, RIF_UNUSED, RIF_SEM_DIS, RIF_CFDIS)
		RIFPROT(RIF_IOPORT_PIN(4), RIF_UNUSED, RIF_UNLOCK, RIF_NSEC, RIF_NPRIV, RIF_UNUSED, RIF_SEM_DIS, RIF_CFDIS)
		RIFPROT(RIF_IOPORT_PIN(5), RIF_UNUSED, RIF_UNLOCK, RIF_NSEC, RIF_NPRIV, RIF_UNUSED, RIF_SEM_DIS, RIF_CFDIS)
		RIFPROT(RIF_IOPORT_PIN(6), RIF_UNUSED, RIF_UNLOCK, RIF_NSEC, RIF_NPRIV, RIF_UNUSED, RIF_SEM_DIS, RIF_CFDIS)
		RIFPROT(RIF_IOPORT_PIN(7), RIF_UNUSED, RIF_UNLOCK, RIF_NSEC, RIF_NPRIV, RIF_UNUSED, RIF_SEM_DIS, RIF_CFDIS)
		RIFPROT(RIF_IOPORT_PIN(8), RIF_UNUSED, RIF_UNLOCK, RIF_NSEC, RIF_NPRIV, RIF_UNUSED, RIF_SEM_DIS, RIF_CFDIS)
		RIFPROT(RIF_IOPORT_PIN(9), RIF_UNUSED, RIF_UNLOCK, RIF_NSEC, RIF_NPRIV, RIF_UNUSED, RIF_SEM_DIS, RIF_CFDIS)
		RIFPROT(RIF_IOPORT_PIN(10), RIF_UNUSED, RIF_UNLOCK, RIF_NSEC, RIF_NPRIV, RIF_UNUSED, RIF_SEM_DIS, RIF_CFDIS)
		RIFPROT(RIF_IOPORT_PIN(11), RIF_UNUSED, RIF_UNLOCK, RIF_NSEC, RIF_NPRIV, RIF_UNUSED, RIF_SEM_DIS, RIF_CFDIS)
		RIFPROT(RIF_IOPORT_PIN(12), RIF_UNUSED, RIF_UNLOCK, RIF_NSEC, RIF_NPRIV, RIF_UNUSED, RIF_SEM_DIS, RIF_CFDIS)
		RIFPROT(RIF_IOPORT_PIN(13), RIF_UNUSED, RIF_UNLOCK, RIF_NSEC, RIF_NPRIV, RIF_UNUSED, RIF_SEM_DIS, RIF_CFDIS)
		RIFPROT(RIF_IOPORT_PIN(14), RIF_UNUSED, RIF_UNLOCK, RIF_SEC, RIF_PRIV, RIF_CID1, RIF_SEM_DIS, RIF_CFEN)
		RIFPROT(RIF_IOPORT_PIN(15), RIF_UNUSED, RIF_UNLOCK, RIF_SEC, RIF_PRIV, RIF_CID1, RIF_SEM_DIS, RIF_CFEN)
	>;
};

&gpioe {
	st,protreg = <
		RIFPROT(RIF_IOPORT_PIN(0), RIF_UNUSED, RIF_UNLOCK, RIF_NSEC, RIF_NPRIV, RIF_UNUSED, RIF_SEM_DIS, RIF_CFDIS)
		RIFPROT(RIF_IOPORT_PIN(1), RIF_UNUSED, RIF_UNLOCK, RIF_NSEC, RIF_NPRIV, RIF_UNUSED, RIF_SEM_DIS, RIF_CFDIS)
		RIFPROT(RIF_IOPORT_PIN(2), RIF_UNUSED, RIF_UNLOCK, RIF_NSEC, RIF_NPRIV, RIF_UNUSED, RIF_SEM_DIS, RIF_CFDIS)
		RIFPROT(RIF_IOPORT_PIN(3), RIF_UNUSED, RIF_UNLOCK, RIF_NSEC, RIF_NPRIV, RIF_UNUSED, RIF_SEM_DIS, RIF_CFDIS)
		RIFPROT(RIF_IOPORT_PIN(4), RIF_UNUSED, RIF_UNLOCK, RIF_NSEC, RIF_NPRIV, RIF_UNUSED, RIF_SEM_DIS, RIF_CFDIS)
		RIFPROT(RIF_IOPORT_PIN(5), RIF_UNUSED, RIF_UNLOCK, RIF_NSEC, RIF_NPRIV, RIF_UNUSED, RIF_SEM_DIS, RIF_CFDIS)
		RIFPROT(RIF_IOPORT_PIN(6), RIF_UNUSED, RIF_UNLOCK, RIF_NSEC, RIF_NPRIV, RIF_UNUSED, RIF_SEM_DIS, RIF_CFDIS)
		RIFPROT(RIF_IOPORT_PIN(7), RIF_UNUSED, RIF_UNLOCK, RIF_NSEC, RIF_NPRIV, RIF_UNUSED, RIF_SEM_DIS, RIF_CFDIS)
		RIFPROT(RIF_IOPORT_PIN(8), RIF_UNUSED, RIF_UNLOCK, RIF_NSEC, RIF_NPRIV, RIF_UNUSED, RIF_SEM_DIS, RIF_CFDIS)
		RIFPROT(RIF_IOPORT_PIN(9), RIF_UNUSED, RIF_UNLOCK, RIF_NSEC, RIF_NPRIV, RIF_UNUSED, RIF_SEM_DIS, RIF_CFDIS)
		RIFPROT(RIF_IOPORT_PIN(10), RIF_UNUSED, RIF_UNLOCK, RIF_NSEC, RIF_NPRIV, RIF_UNUSED, RIF_SEM_DIS, RIF_CFDIS)
		RIFPROT(RIF_IOPORT_PIN(11), RIF_UNUSED, RIF_UNLOCK, RIF_NSEC, RIF_NPRIV, RIF_UNUSED, RIF_SEM_DIS, RIF_CFDIS)
		RIFPROT(RIF_IOPORT_PIN(12), RIF_UNUSED, RIF_UNLOCK, RIF_NSEC, RIF_NPRIV, RIF_UNUSED, RIF_SEM_DIS, RIF_CFDIS)
		RIFPROT(RIF_IOPORT_PIN(13), RIF_UNUSED, RIF_UNLOCK, RIF_NSEC, RIF_NPRIV, RIF_UNUSED, RIF_SEM_DIS, RIF_CFDIS)
		RIFPROT(RIF_IOPORT_PIN(14), RIF_UNUSED, RIF_UNLOCK, RIF_NSEC, RIF_NPRIV, RIF_UNUSED, RIF_SEM_DIS, RIF_CFDIS)
		RIFPROT(RIF_IOPORT_PIN(15), RIF_UNUSED, RIF_UNLOCK, RIF_NSEC, RIF_NPRIV, RIF_UNUSED, RIF_SEM_DIS, RIF_CFDIS)
	>;
};

&gpiof {
	st,protreg = <
		RIFPROT(RIF_IOPORT_PIN(0), RIF_UNUSED, RIF_UNLOCK, RIF_NSEC, RIF_NPRIV, RIF_UNUSED, RIF_SEM_DIS, RIF_CFDIS)
		RIFPROT(RIF_IOPORT_PIN(1), RIF_UNUSED, RIF_UNLOCK, RIF_NSEC, RIF_NPRIV, RIF_UNUSED, RIF_SEM_DIS, RIF_CFDIS)
		RIFPROT(RIF_IOPORT_PIN(2), RIF_UNUSED, RIF_UNLOCK, RIF_NSEC, RIF_NPRIV, RIF_UNUSED, RIF_SEM_DIS, RIF_CFDIS)
		RIFPROT(RIF_IOPORT_PIN(3), RIF_UNUSED, RIF_UNLOCK, RIF_NSEC, RIF_NPRIV, RIF_UNUSED, RIF_SEM_DIS, RIF_CFDIS)
		RIFPROT(RIF_IOPORT_PIN(4), RIF_UNUSED, RIF_UNLOCK, RIF_NSEC, RIF_NPRIV, RIF_UNUSED, RIF_SEM_DIS, RIF_CFDIS)
		RIFPROT(RIF_IOPORT_PIN(5), RIF_UNUSED, RIF_UNLOCK, RIF_NSEC, RIF_NPRIV, RIF_UNUSED, RIF_SEM_DIS, RIF_CFDIS)
		RIFPROT(RIF_IOPORT_PIN(6), RIF_UNUSED, RIF_UNLOCK, RIF_NSEC, RIF_NPRIV, RIF_UNUSED, RIF_SEM_DIS, RIF_CFDIS)
		RIFPROT(RIF_IOPORT_PIN(7), RIF_UNUSED, RIF_UNLOCK, RIF_NSEC, RIF_NPRIV, RIF_UNUSED, RIF_SEM_DIS, RIF_CFDIS)
		RIFPROT(RIF_IOPORT_PIN(8), RIF_UNUSED, RIF_UNLOCK, RIF_NSEC, RIF_NPRIV, RIF_UNUSED, RIF_SEM_DIS, RIF_CFDIS)
		RIFPROT(RIF_IOPORT_PIN(9), RIF_UNUSED, RIF_UNLOCK, RIF_NSEC, RIF_NPRIV, RIF_UNUSED, RIF_SEM_DIS, RIF_CFDIS)
		RIFPROT(RIF_IOPORT_PIN(10), RIF_UNUSED, RIF_UNLOCK, RIF_NSEC, RIF_NPRIV, RIF_UNUSED, RIF_SEM_DIS, RIF_CFDIS)
		RIFPROT(RIF_IOPORT_PIN(11), RIF_UNUSED, RIF_UNLOCK, RIF_NSEC, RIF_NPRIV, RIF_UNUSED, RIF_SEM_DIS, RIF_CFDIS)
		RIFPROT(RIF_IOPORT_PIN(12), RIF_UNUSED, RIF_UNLOCK, RIF_NSEC, RIF_NPRIV, RIF_UNUSED, RIF_SEM_DIS, RIF_CFDIS)
		RIFPROT(RIF_IOPORT_PIN(13), RIF_UNUSED, RIF_UNLOCK, RIF_NSEC, RIF_NPRIV, RIF_UNUSED, RIF_SEM_DIS, RIF_CFDIS)
		RIFPROT(RIF_IOPORT_PIN(14), RIF_UNUSED, RIF_UNLOCK, RIF_NSEC, RIF_NPRIV, RIF_UNUSED, RIF_SEM_DIS, RIF_CFDIS)
		RIFPROT(RIF_IOPORT_PIN(15), RIF_UNUSED, RIF_UNLOCK, RIF_NSEC, RIF_NPRIV, RIF_UNUSED, RIF_SEM_DIS, RIF_CFDIS)
	>;
};

&gpiog {
	st,protreg = <
		RIFPROT(RIF_IOPORT_PIN(0), RIF_UNUSED, RIF_UNLOCK, RIF_NSEC, RIF_NPRIV, RIF_UNUSED, RIF_SEM_DIS, RIF_CFDIS)
		RIFPROT(RIF_IOPORT_PIN(1), RIF_UNUSED, RIF_UNLOCK, RIF_NSEC, RIF_NPRIV, RIF_UNUSED, RIF_SEM_DIS, RIF_CFDIS)
		RIFPROT(RIF_IOPORT_PIN(2), RIF_UNUSED, RIF_UNLOCK, RIF_NSEC, RIF_NPRIV, RIF_UNUSED, RIF_SEM_DIS, RIF_CFDIS)
		RIFPROT(RIF_IOPORT_PIN(3), RIF_UNUSED, RIF_UNLOCK, RIF_NSEC, RIF_NPRIV, RIF_UNUSED, RIF_SEM_DIS, RIF_CFDIS)
		RIFPROT(RIF_IOPORT_PIN(4), RIF_UNUSED, RIF_UNLOCK, RIF_NSEC, RIF_NPRIV, RIF_UNUSED, RIF_SEM_DIS, RIF_CFDIS)
		RIFPROT(RIF_IOPORT_PIN(5), RIF_UNUSED, RIF_UNLOCK, RIF_NSEC, RIF_NPRIV, RIF_UNUSED, RIF_SEM_DIS, RIF_CFDIS)
		RIFPROT(RIF_IOPORT_PIN(6), RIF_UNUSED, RIF_UNLOCK, RIF_NSEC, RIF_NPRIV, RIF_UNUSED, RIF_SEM_DIS, RIF_CFDIS)
		RIFPROT(RIF_IOPORT_PIN(7), RIF_UNUSED, RIF_UNLOCK, RIF_NSEC, RIF_NPRIV, RIF_UNUSED, RIF_SEM_DIS, RIF_CFDIS)
		RIFPROT(RIF_IOPORT_PIN(8), RIF_UNUSED, RIF_UNLOCK, RIF_NSEC, RIF_NPRIV, RIF_UNUSED, RIF_SEM_DIS, RIF_CFDIS)
		RIFPROT(RIF_IOPORT_PIN(9), RIF_UNUSED, RIF_UNLOCK, RIF_NSEC, RIF_NPRIV, RIF_UNUSED, RIF_SEM_DIS, RIF_CFDIS)
		RIFPROT(RIF_IOPORT_PIN(10), RIF_UNUSED, RIF_UNLOCK, RIF_NSEC, RIF_NPRIV, RIF_UNUSED, RIF_SEM_DIS, RIF_CFDIS)
		RIFPROT(RIF_IOPORT_PIN(11), RIF_UNUSED, RIF_UNLOCK, RIF_NSEC, RIF_NPRIV, RIF_UNUSED, RIF_SEM_DIS, RIF_CFDIS)
		RIFPROT(RIF_IOPORT_PIN(12), RIF_UNUSED, RIF_UNLOCK, RIF_NSEC, RIF_NPRIV, RIF_UNUSED, RIF_SEM_DIS, RIF_CFDIS)
		RIFPROT(RIF_IOPORT_PIN(13), RIF_UNUSED, RIF_UNLOCK, RIF_NSEC, RIF_NPRIV, RIF_UNUSED, RIF_SEM_DIS, RIF_CFDIS)
		RIFPROT(RIF_IOPORT_PIN(14), RIF_UNUSED, RIF_UNLOCK, RIF_NSEC, RIF_NPRIV, RIF_UNUSED, RIF_SEM_DIS, RIF_CFDIS)
		RIFPROT(RIF_IOPORT_PIN(15), RIF_UNUSED, RIF_UNLOCK, RIF_NSEC, RIF_NPRIV, RIF_UNUSED, RIF_SEM_DIS, RIF_CFDIS)
	>;
};

&gpioh {
	st,protreg = <
		RIFPROT(RIF_IOPORT_PIN(0), RIF_UNUSED, RIF_UNLOCK, RIF_NSEC, RIF_NPRIV, RIF_UNUSED, RIF_SEM_DIS, RIF_CFDIS)
		RIFPROT(RIF_IOPORT_PIN(1), RIF_UNUSED, RIF_UNLOCK, RIF_NSEC, RIF_NPRIV, RIF_UNUSED, RIF_SEM_DIS, RIF_CFDIS)
		RIFPROT(RIF_IOPORT_PIN(2), RIF_UNUSED, RIF_UNLOCK, RIF_NSEC, RIF_NPRIV, RIF_UNUSED, RIF_SEM_DIS, RIF_CFDIS)
		RIFPROT(RIF_IOPORT_PIN(3), RIF_UNUSED, RIF_UNLOCK, RIF_NSEC, RIF_NPRIV, RIF_UNUSED, RIF_SEM_DIS, RIF_CFDIS)
		RIFPROT(RIF_IOPORT_PIN(4), RIF_UNUSED, RIF_UNLOCK, RIF_SEC, RIF_PRIV, RIF_CID1, RIF_SEM_DIS, RIF_CFEN)
		RIFPROT(RIF_IOPORT_PIN(5), RIF_UNUSED, RIF_UNLOCK, RIF_NSEC, RIF_NPRIV, RIF_UNUSED, RIF_SEM_DIS, RIF_CFDIS)
		RIFPROT(RIF_IOPORT_PIN(6), RIF_UNUSED, RIF_UNLOCK, RIF_NSEC, RIF_NPRIV, RIF_UNUSED, RIF_SEM_DIS, RIF_CFDIS)
		RIFPROT(RIF_IOPORT_PIN(7), RIF_UNUSED, RIF_UNLOCK, RIF_NSEC, RIF_NPRIV, RIF_UNUSED, RIF_SEM_DIS, RIF_CFDIS)
		RIFPROT(RIF_IOPORT_PIN(8), RIF_UNUSED, RIF_UNLOCK, RIF_NSEC, RIF_NPRIV, RIF_UNUSED, RIF_SEM_DIS, RIF_CFDIS)
		RIFPROT(RIF_IOPORT_PIN(9), RIF_UNUSED, RIF_UNLOCK, RIF_NSEC, RIF_NPRIV, RIF_UNUSED, RIF_SEM_DIS, RIF_CFDIS)
		RIFPROT(RIF_IOPORT_PIN(10), RIF_UNUSED, RIF_UNLOCK, RIF_NSEC, RIF_NPRIV, RIF_UNUSED, RIF_SEM_DIS, RIF_CFDIS)
		RIFPROT(RIF_IOPORT_PIN(11), RIF_UNUSED, RIF_UNLOCK, RIF_NSEC, RIF_NPRIV, RIF_UNUSED, RIF_SEM_DIS, RIF_CFDIS)
		RIFPROT(RIF_IOPORT_PIN(12), RIF_UNUSED, RIF_UNLOCK, RIF_NSEC, RIF_NPRIV, RIF_UNUSED, RIF_SEM_DIS, RIF_CFDIS)
		RIFPROT(RIF_IOPORT_PIN(13), RIF_UNUSED, RIF_UNLOCK, RIF_NSEC, RIF_NPRIV, RIF_UNUSED, RIF_SEM_DIS, RIF_CFDIS)
	>;
};

&gpioi {
	st,protreg = <
		RIFPROT(RIF_IOPORT_PIN(0), RIF_UNUSED, RIF_UNLOCK, RIF_NSEC, RIF_NPRIV, RIF_UNUSED, RIF_SEM_DIS, RIF_CFDIS)
		RIFPROT(RIF_IOPORT_PIN(1), RIF_UNUSED, RIF_UNLOCK, RIF_NSEC, RIF_NPRIV, RIF_UNUSED, RIF_SEM_DIS, RIF_CFDIS)
		RIFPROT(RIF_IOPORT_PIN(2), RIF_UNUSED, RIF_UNLOCK, RIF_NSEC, RIF_NPRIV, RIF_UNUSED, RIF_SEM_DIS, RIF_CFDIS)
		RIFPROT(RIF_IOPORT_PIN(3), RIF_UNUSED, RIF_UNLOCK, RIF_NSEC, RIF_NPRIV, RIF_UNUSED, RIF_SEM_DIS, RIF_CFDIS)
		RIFPROT(RIF_IOPORT_PIN(4), RIF_UNUSED, RIF_UNLOCK, RIF_NSEC, RIF_NPRIV, RIF_UNUSED, RIF_SEM_DIS, RIF_CFDIS)
		RIFPROT(RIF_IOPORT_PIN(5), RIF_UNUSED, RIF_UNLOCK, RIF_NSEC, RIF_NPRIV, RIF_UNUSED, RIF_SEM_DIS, RIF_CFDIS)
		RIFPROT(RIF_IOPORT_PIN(6), RIF_UNUSED, RIF_UNLOCK, RIF_NSEC, RIF_NPRIV, RIF_UNUSED, RIF_SEM_DIS, RIF_CFDIS)
		RIFPROT(RIF_IOPORT_PIN(7), RIF_UNUSED, RIF_UNLOCK, RIF_NSEC, RIF_NPRIV, RIF_UNUSED, RIF_SEM_DIS, RIF_CFDIS)
		RIFPROT(RIF_IOPORT_PIN(8), RIF_UNUSED, RIF_UNLOCK, RIF_SEC, RIF_PRIV, RIF_CID1, RIF_SEM_DIS, RIF_CFEN)
		RIFPROT(RIF_IOPORT_PIN(9), RIF_UNUSED, RIF_UNLOCK, RIF_NSEC, RIF_NPRIV, RIF_UNUSED, RIF_SEM_DIS, RIF_CFDIS)
		RIFPROT(RIF_IOPORT_PIN(10), RIF_UNUSED, RIF_UNLOCK, RIF_NSEC, RIF_NPRIV, RIF_UNUSED, RIF_SEM_DIS, RIF_CFDIS)
		RIFPROT(RIF_IOPORT_PIN(11), RIF_UNUSED, RIF_UNLOCK, RIF_NSEC, RIF_NPRIV, RIF_UNUSED, RIF_SEM_DIS, RIF_CFDIS)
		RIFPROT(RIF_IOPORT_PIN(12), RIF_UNUSED, RIF_UNLOCK, RIF_NSEC, RIF_NPRIV, RIF_UNUSED, RIF_SEM_DIS, RIF_CFDIS)
		RIFPROT(RIF_IOPORT_PIN(13), RIF_UNUSED, RIF_UNLOCK, RIF_NSEC, RIF_NPRIV, RIF_UNUSED, RIF_SEM_DIS, RIF_CFDIS)
		RIFPROT(RIF_IOPORT_PIN(14), RIF_UNUSED, RIF_UNLOCK, RIF_NSEC, RIF_NPRIV, RIF_UNUSED, RIF_SEM_DIS, RIF_CFDIS)
		RIFPROT(RIF_IOPORT_PIN(15), RIF_UNUSED, RIF_UNLOCK, RIF_NSEC, RIF_NPRIV, RIF_UNUSED, RIF_SEM_DIS, RIF_CFDIS)
	>;
};

&gpioj {
	st,protreg = <
		RIFPROT(RIF_IOPORT_PIN(0), RIF_UNUSED, RIF_UNLOCK, RIF_NSEC, RIF_NPRIV, RIF_UNUSED, RIF_SEM_DIS, RIF_CFDIS)
		RIFPROT(RIF_IOPORT_PIN(1), RIF_UNUSED, RIF_UNLOCK, RIF_NSEC, RIF_NPRIV, RIF_UNUSED, RIF_SEM_DIS, RIF_CFDIS)
		RIFPROT(RIF_IOPORT_PIN(2), RIF_UNUSED, RIF_UNLOCK, RIF_NSEC, RIF_NPRIV, RIF_UNUSED, RIF_SEM_DIS, RIF_CFDIS)
		RIFPROT(RIF_IOPORT_PIN(3), RIF_UNUSED, RIF_UNLOCK, RIF_NSEC, RIF_NPRIV, RIF_UNUSED, RIF_SEM_DIS, RIF_CFDIS)
		RIFPROT(RIF_IOPORT_PIN(4), RIF_UNUSED, RIF_UNLOCK, RIF_NSEC, RIF_NPRIV, RIF_UNUSED, RIF_SEM_DIS, RIF_CFDIS)
		RIFPROT(RIF_IOPORT_PIN(5), RIF_UNUSED, RIF_UNLOCK, RIF_NSEC, RIF_NPRIV, RIF_UNUSED, RIF_SEM_DIS, RIF_CFDIS)
		RIFPROT(RIF_IOPORT_PIN(6), RIF_UNUSED, RIF_UNLOCK, RIF_NSEC, RIF_NPRIV, RIF_UNUSED, RIF_SEM_DIS, RIF_CFDIS)
		RIFPROT(RIF_IOPORT_PIN(7), RIF_UNUSED, RIF_UNLOCK, RIF_NSEC, RIF_NPRIV, RIF_UNUSED, RIF_SEM_DIS, RIF_CFDIS)
		RIFPROT(RIF_IOPORT_PIN(8), RIF_UNUSED, RIF_UNLOCK, RIF_NSEC, RIF_NPRIV, RIF_UNUSED, RIF_SEM_DIS, RIF_CFDIS)
		RIFPROT(RIF_IOPORT_PIN(9), RIF_UNUSED, RIF_UNLOCK, RIF_NSEC, RIF_NPRIV, RIF_UNUSED, RIF_SEM_DIS, RIF_CFDIS)
		RIFPROT(RIF_IOPORT_PIN(10), RIF_UNUSED, RIF_UNLOCK, RIF_NSEC, RIF_NPRIV, RIF_UNUSED, RIF_SEM_DIS, RIF_CFDIS)
		RIFPROT(RIF_IOPORT_PIN(11), RIF_UNUSED, RIF_UNLOCK, RIF_NSEC, RIF_NPRIV, RIF_UNUSED, RIF_SEM_DIS, RIF_CFDIS)
		RIFPROT(RIF_IOPORT_PIN(12), RIF_UNUSED, RIF_UNLOCK, RIF_NSEC, RIF_NPRIV, RIF_UNUSED, RIF_SEM_DIS, RIF_CFDIS)
		RIFPROT(RIF_IOPORT_PIN(13), RIF_UNUSED, RIF_UNLOCK, RIF_NSEC, RIF_NPRIV, RIF_UNUSED, RIF_SEM_DIS, RIF_CFDIS)
		RIFPROT(RIF_IOPORT_PIN(14), RIF_UNUSED, RIF_UNLOCK, RIF_NSEC, RIF_NPRIV, RIF_UNUSED, RIF_SEM_DIS, RIF_CFDIS)
		RIFPROT(RIF_IOPORT_PIN(15), RIF_UNUSED, RIF_UNLOCK, RIF_NSEC, RIF_NPRIV, RIF_UNUSED, RIF_SEM_DIS, RIF_CFDIS)
	>;
};

&gpiok {
	st,protreg = <
		RIFPROT(RIF_IOPORT_PIN(0), RIF_UNUSED, RIF_UNLOCK, RIF_NSEC, RIF_NPRIV, RIF_UNUSED, RIF_SEM_DIS, RIF_CFDIS)
		RIFPROT(RIF_IOPORT_PIN(1), RIF_UNUSED, RIF_UNLOCK, RIF_NSEC, RIF_NPRIV, RIF_UNUSED, RIF_SEM_DIS, RIF_CFDIS)
		RIFPROT(RIF_IOPORT_PIN(2), RIF_UNUSED, RIF_UNLOCK, RIF_NSEC, RIF_NPRIV, RIF_UNUSED, RIF_SEM_DIS, RIF_CFDIS)
		RIFPROT(RIF_IOPORT_PIN(3), RIF_UNUSED, RIF_UNLOCK, RIF_NSEC, RIF_NPRIV, RIF_UNUSED, RIF_SEM_DIS, RIF_CFDIS)
		RIFPROT(RIF_IOPORT_PIN(4), RIF_UNUSED, RIF_UNLOCK, RIF_NSEC, RIF_NPRIV, RIF_UNUSED, RIF_SEM_DIS, RIF_CFDIS)
		RIFPROT(RIF_IOPORT_PIN(5), RIF_UNUSED, RIF_UNLOCK, RIF_NSEC, RIF_NPRIV, RIF_UNUSED, RIF_SEM_DIS, RIF_CFDIS)
		RIFPROT(RIF_IOPORT_PIN(6), RIF_UNUSED, RIF_UNLOCK, RIF_NSEC, RIF_NPRIV, RIF_UNUSED, RIF_SEM_DIS, RIF_CFDIS)
		RIFPROT(RIF_IOPORT_PIN(7), RIF_UNUSED, RIF_UNLOCK, RIF_NSEC, RIF_NPRIV, RIF_UNUSED, RIF_SEM_DIS, RIF_CFDIS)
	>;
};

&gpioz {
	st,protreg = <
		RIFPROT(RIF_IOPORT_PIN(0), RIF_UNUSED, RIF_UNLOCK, RIF_NSEC, RIF_NPRIV, RIF_UNUSED, RIF_SEM_DIS, RIF_CFDIS)
		RIFPROT(RIF_IOPORT_PIN(1), RIF_UNUSED, RIF_UNLOCK, RIF_NSEC, RIF_NPRIV, RIF_UNUSED, RIF_SEM_DIS, RIF_CFDIS)
		RIFPROT(RIF_IOPORT_PIN(2), RIF_UNUSED, RIF_UNLOCK, RIF_NSEC, RIF_NPRIV, RIF_UNUSED, RIF_SEM_DIS, RIF_CFDIS)
		RIFPROT(RIF_IOPORT_PIN(3), RIF_UNUSED, RIF_UNLOCK, RIF_NSEC, RIF_NPRIV, RIF_UNUSED, RIF_SEM_DIS, RIF_CFDIS)
		RIFPROT(RIF_IOPORT_PIN(4), RIF_UNUSED, RIF_UNLOCK, RIF_NSEC, RIF_NPRIV, RIF_UNUSED, RIF_SEM_DIS, RIF_CFDIS)
		RIFPROT(RIF_IOPORT_PIN(5), RIF_UNUSED, RIF_UNLOCK, RIF_NSEC, RIF_NPRIV, RIF_UNUSED, RIF_SEM_DIS, RIF_CFDIS)
		RIFPROT(RIF_IOPORT_PIN(6), RIF_UNUSED, RIF_UNLOCK, RIF_NSEC, RIF_NPRIV, RIF_UNUSED, RIF_SEM_DIS, RIF_CFDIS)
		RIFPROT(RIF_IOPORT_PIN(7), RIF_UNUSED, RIF_UNLOCK, RIF_NSEC, RIF_NPRIV, RIF_CID3, RIF_SEM_DIS, RIF_CFEN)
		RIFPROT(RIF_IOPORT_PIN(8), RIF_UNUSED, RIF_UNLOCK, RIF_NSEC, RIF_NPRIV, RIF_CID3, RIF_SEM_DIS, RIF_CFEN)
		RIFPROT(RIF_IOPORT_PIN(9), RIF_UNUSED, RIF_UNLOCK, RIF_NSEC, RIF_NPRIV, RIF_UNUSED, RIF_SEM_DIS, RIF_CFDIS)
	>;
};

&hpdma1 {
	st,protreg = <
		RIFPROT(RIF_HPDMA_CHANNEL(0), RIF_UNUSED, RIF_UNLOCK, RIF_NSEC, RIF_PRIV, RIF_CID1, RIF_SEM_DIS, RIF_CFEN)
		RIFPROT(RIF_HPDMA_CHANNEL(1), RIF_UNUSED, RIF_UNLOCK, RIF_NSEC, RIF_PRIV, RIF_CID1, RIF_SEM_DIS, RIF_CFEN)
		RIFPROT(RIF_HPDMA_CHANNEL(2), RIF_UNUSED, RIF_UNLOCK, RIF_NSEC, RIF_PRIV, RIF_CID1, RIF_SEM_DIS, RIF_CFEN)
		RIFPROT(RIF_HPDMA_CHANNEL(3), RIF_UNUSED, RIF_UNLOCK, RIF_NSEC, RIF_PRIV, RIF_CID1, RIF_SEM_DIS, RIF_CFEN)
		RIFPROT(RIF_HPDMA_CHANNEL(4), RIF_UNUSED, RIF_UNLOCK, RIF_NSEC, RIF_PRIV, RIF_CID1, RIF_SEM_DIS, RIF_CFEN)
		RIFPROT(RIF_HPDMA_CHANNEL(5), RIF_UNUSED, RIF_UNLOCK, RIF_NSEC, RIF_PRIV, RIF_CID1, RIF_SEM_DIS, RIF_CFEN)
		RIFPROT(RIF_HPDMA_CHANNEL(6), RIF_UNUSED, RIF_UNLOCK, RIF_NSEC, RIF_PRIV, RIF_CID1, RIF_SEM_DIS, RIF_CFEN)
		RIFPROT(RIF_HPDMA_CHANNEL(7), RIF_UNUSED, RIF_UNLOCK, RIF_NSEC, RIF_PRIV, RIF_CID1, RIF_SEM_DIS, RIF_CFEN)
		RIFPROT(RIF_HPDMA_CHANNEL(8), RIF_UNUSED, RIF_UNLOCK, RIF_NSEC, RIF_PRIV, RIF_CID1, RIF_SEM_DIS, RIF_CFEN)
		RIFPROT(RIF_HPDMA_CHANNEL(9), RIF_UNUSED, RIF_UNLOCK, RIF_NSEC, RIF_PRIV, RIF_CID1, RIF_SEM_DIS, RIF_CFEN)
		RIFPROT(RIF_HPDMA_CHANNEL(10), RIF_UNUSED, RIF_UNLOCK, RIF_NSEC, RIF_PRIV, RIF_CID1, RIF_SEM_DIS, RIF_CFEN)
		RIFPROT(RIF_HPDMA_CHANNEL(11), RIF_UNUSED, RIF_UNLOCK, RIF_NSEC, RIF_PRIV, RIF_CID1, RIF_SEM_DIS, RIF_CFEN)
		RIFPROT(RIF_HPDMA_CHANNEL(12), RIF_UNUSED, RIF_UNLOCK, RIF_NSEC, RIF_PRIV, RIF_CID1, RIF_SEM_DIS, RIF_CFEN)
		RIFPROT(RIF_HPDMA_CHANNEL(13), RIF_UNUSED, RIF_UNLOCK, RIF_NSEC, RIF_PRIV, RIF_CID1, RIF_SEM_DIS, RIF_CFEN)
		RIFPROT(RIF_HPDMA_CHANNEL(14), RIF_UNUSED, RIF_UNLOCK, RIF_NSEC, RIF_PRIV, RIF_CID1, RIF_SEM_DIS, RIF_CFEN)
		RIFPROT(RIF_HPDMA_CHANNEL(15), RIF_UNUSED, RIF_UNLOCK, RIF_NSEC, RIF_PRIV, RIF_CID1, RIF_SEM_DIS, RIF_CFEN)
	>;
};

&hpdma2 {
	st,protreg = <
		RIFPROT(RIF_HPDMA_CHANNEL(0), RIF_UNUSED, RIF_UNLOCK, RIF_NSEC, RIF_PRIV, RIF_CID1, RIF_SEM_DIS, RIF_CFEN)
		RIFPROT(RIF_HPDMA_CHANNEL(1), RIF_UNUSED, RIF_UNLOCK, RIF_NSEC, RIF_PRIV, RIF_CID1, RIF_SEM_DIS, RIF_CFEN)
		RIFPROT(RIF_HPDMA_CHANNEL(2), RIF_UNUSED, RIF_UNLOCK, RIF_NSEC, RIF_PRIV, RIF_CID1, RIF_SEM_DIS, RIF_CFEN)
		RIFPROT(RIF_HPDMA_CHANNEL(3), RIF_UNUSED, RIF_UNLOCK, RIF_NSEC, RIF_PRIV, RIF_CID1, RIF_SEM_DIS, RIF_CFEN)
		RIFPROT(RIF_HPDMA_CHANNEL(4), RIF_UNUSED, RIF_UNLOCK, RIF_NSEC, RIF_PRIV, RIF_CID1, RIF_SEM_DIS, RIF_CFEN)
		RIFPROT(RIF_HPDMA_CHANNEL(5), RIF_UNUSED, RIF_UNLOCK, RIF_NSEC, RIF_PRIV, RIF_CID1, RIF_SEM_DIS, RIF_CFEN)
		RIFPROT(RIF_HPDMA_CHANNEL(6), RIF_UNUSED, RIF_UNLOCK, RIF_NSEC, RIF_PRIV, RIF_CID1, RIF_SEM_DIS, RIF_CFEN)
		RIFPROT(RIF_HPDMA_CHANNEL(7), RIF_UNUSED, RIF_UNLOCK, RIF_NSEC, RIF_PRIV, RIF_CID1, RIF_SEM_DIS, RIF_CFEN)
		RIFPROT(RIF_HPDMA_CHANNEL(8), RIF_UNUSED, RIF_UNLOCK, RIF_NSEC, RIF_PRIV, RIF_CID1, RIF_SEM_DIS, RIF_CFEN)
		RIFPROT(RIF_HPDMA_CHANNEL(9), RIF_UNUSED, RIF_UNLOCK, RIF_NSEC, RIF_PRIV, RIF_CID1, RIF_SEM_DIS, RIF_CFEN)
		RIFPROT(RIF_HPDMA_CHANNEL(10), RIF_UNUSED, RIF_UNLOCK, RIF_NSEC, RIF_PRIV, RIF_CID1, RIF_SEM_DIS, RIF_CFEN)
		RIFPROT(RIF_HPDMA_CHANNEL(11), RIF_UNUSED, RIF_UNLOCK, RIF_NSEC, RIF_PRIV, RIF_CID1, RIF_SEM_DIS, RIF_CFEN)
		RIFPROT(RIF_HPDMA_CHANNEL(12), RIF_UNUSED, RIF_UNLOCK, RIF_NSEC, RIF_PRIV, RIF_CID1, RIF_SEM_DIS, RIF_CFEN)
		RIFPROT(RIF_HPDMA_CHANNEL(13), RIF_UNUSED, RIF_UNLOCK, RIF_NSEC, RIF_PRIV, RIF_CID1, RIF_SEM_DIS, RIF_CFEN)
		RIFPROT(RIF_HPDMA_CHANNEL(14), RIF_UNUSED, RIF_UNLOCK, RIF_NSEC, RIF_PRIV, RIF_CID1, RIF_SEM_DIS, RIF_CFEN)
		RIFPROT(RIF_HPDMA_CHANNEL(15), RIF_UNUSED, RIF_UNLOCK, RIF_NSEC, RIF_PRIV, RIF_CID1, RIF_SEM_DIS, RIF_CFEN)
	>;
};

&hpdma3 {
	st,protreg = <
		RIFPROT(RIF_HPDMA_CHANNEL(0), RIF_UNUSED, RIF_UNLOCK, RIF_NSEC, RIF_PRIV, RIF_CID2, RIF_SEM_DIS, RIF_CFEN)
		RIFPROT(RIF_HPDMA_CHANNEL(1), RIF_UNUSED, RIF_UNLOCK, RIF_NSEC, RIF_PRIV, RIF_CID2, RIF_SEM_DIS, RIF_CFEN)
		RIFPROT(RIF_HPDMA_CHANNEL(2), RIF_UNUSED, RIF_UNLOCK, RIF_NSEC, RIF_PRIV, RIF_CID2, RIF_SEM_DIS, RIF_CFEN)
		RIFPROT(RIF_HPDMA_CHANNEL(3), RIF_UNUSED, RIF_UNLOCK, RIF_NSEC, RIF_PRIV, RIF_CID2, RIF_SEM_DIS, RIF_CFEN)
		RIFPROT(RIF_HPDMA_CHANNEL(4), RIF_UNUSED, RIF_UNLOCK, RIF_NSEC, RIF_PRIV, RIF_CID2, RIF_SEM_DIS, RIF_CFEN)
		RIFPROT(RIF_HPDMA_CHANNEL(5), RIF_UNUSED, RIF_UNLOCK, RIF_NSEC, RIF_PRIV, RIF_CID2, RIF_SEM_DIS, RIF_CFEN)
		RIFPROT(RIF_HPDMA_CHANNEL(6), RIF_UNUSED, RIF_UNLOCK, RIF_NSEC, RIF_PRIV, RIF_CID2, RIF_SEM_DIS, RIF_CFEN)
		RIFPROT(RIF_HPDMA_CHANNEL(7), RIF_UNUSED, RIF_UNLOCK, RIF_NSEC, RIF_PRIV, RIF_CID2, RIF_SEM_DIS, RIF_CFEN)
		RIFPROT(RIF_HPDMA_CHANNEL(8), RIF_UNUSED, RIF_UNLOCK, RIF_NSEC, RIF_PRIV, RIF_CID2, RIF_SEM_DIS, RIF_CFEN)
		RIFPROT(RIF_HPDMA_CHANNEL(9), RIF_UNUSED, RIF_UNLOCK, RIF_NSEC, RIF_PRIV, RIF_CID2, RIF_SEM_DIS, RIF_CFEN)
		RIFPROT(RIF_HPDMA_CHANNEL(10), RIF_UNUSED, RIF_UNLOCK, RIF_NSEC, RIF_PRIV, RIF_CID2, RIF_SEM_DIS, RIF_CFEN)
		RIFPROT(RIF_HPDMA_CHANNEL(11), RIF_UNUSED, RIF_UNLOCK, RIF_NSEC, RIF_PRIV, RIF_CID2, RIF_SEM_DIS, RIF_CFEN)
		RIFPROT(RIF_HPDMA_CHANNEL(12), RIF_UNUSED, RIF_UNLOCK, RIF_NSEC, RIF_PRIV, RIF_CID2, RIF_SEM_DIS, RIF_CFEN)
		RIFPROT(RIF_HPDMA_CHANNEL(13), RIF_UNUSED, RIF_UNLOCK, RIF_NSEC, RIF_PRIV, RIF_CID2, RIF_SEM_DIS, RIF_CFEN)
		RIFPROT(RIF_HPDMA_CHANNEL(14), RIF_UNUSED, RIF_UNLOCK, RIF_NSEC, RIF_PRIV, RIF_CID1, RIF_SEM_DIS, RIF_CFEN)
		RIFPROT(RIF_HPDMA_CHANNEL(15), RIF_UNUSED, RIF_UNLOCK, RIF_NSEC, RIF_PRIV, RIF_CID1, RIF_SEM_DIS, RIF_CFEN)
	>;
};

&rcc {
	st,protreg = <
		RIFPROT(RIF_RCC_RESOURCE(69), RIF_UNUSED, RIF_UNLOCK, RIF_SEC, RIF_PRIV, RIF_CID1, RIF_SEM_DIS, RIF_CFEN)
		RIFPROT(RIF_RCC_RESOURCE(64), RIF_UNUSED, RIF_UNLOCK, RIF_SEC, RIF_PRIV, RIF_CID1, RIF_SEM_DIS, RIF_CFEN)
		RIFPROT(RIF_RCC_RESOURCE(65), RIF_UNUSED, RIF_UNLOCK, RIF_SEC, RIF_PRIV, RIF_CID1, RIF_SEM_DIS, RIF_CFEN)
		RIFPROT(RIF_RCC_RESOURCE(66), RIF_UNUSED, RIF_UNLOCK, RIF_SEC, RIF_PRIV, RIF_CID1, RIF_SEM_DIS, RIF_CFEN)
		RIFPROT(RIF_RCC_RESOURCE(67), RIF_UNUSED, RIF_UNLOCK, RIF_SEC, RIF_PRIV, RIF_CID1, RIF_SEM_DIS, RIF_CFEN)
		RIFPROT(RIF_RCC_RESOURCE(68), RIF_UNUSED, RIF_UNLOCK, RIF_SEC, RIF_PRIV, RIF_CID1, RIF_SEM_DIS, RIF_CFEN)
		RIFPROT(RIF_RCC_RESOURCE(70), RIF_UNUSED, RIF_UNLOCK, RIF_SEC, RIF_PRIV, RIF_CID1, RIF_SEM_DIS, RIF_CFEN)
		RIFPROT(RIF_RCC_RESOURCE(71), RIF_UNUSED, RIF_UNLOCK, RIF_SEC, RIF_PRIV, RIF_CID2, RIF_SEM_DIS, RIF_CFEN)
		RIFPROT(RIF_RCC_RESOURCE(72), RIF_UNUSED, RIF_UNLOCK, RIF_NSEC, RIF_NPRIV, RIF_UNUSED, RIF_SEM_DIS, RIF_CFDIS)
		RIFPROT(RIF_RCC_RESOURCE(73), RIF_CID1_BF, RIF_UNLOCK, RIF_SEC, RIF_PRIV, RIF_UNUSED, RIF_SEM_EN, RIF_CFEN)
		RIFPROT(RIF_RCC_RESOURCE(74), RIF_CID1_BF, RIF_UNLOCK, RIF_SEC, RIF_PRIV, RIF_UNUSED, RIF_SEM_EN, RIF_CFEN)
		RIFPROT(RIF_RCC_RESOURCE(75), RIF_UNUSED, RIF_UNLOCK, RIF_SEC, RIF_PRIV, RIF_CID1, RIF_SEM_DIS, RIF_CFEN)
		RIFPROT(RIF_RCC_RESOURCE(76), RIF_CID1_BF, RIF_UNLOCK, RIF_SEC, RIF_PRIV, RIF_UNUSED, RIF_SEM_EN, RIF_CFEN)
		RIFPROT(RIF_RCC_RESOURCE(77), RIF_CID1_BF, RIF_UNLOCK, RIF_SEC, RIF_PRIV, RIF_UNUSED, RIF_SEM_EN, RIF_CFEN)
		RIFPROT(RIF_RCC_RESOURCE(78), RIF_CID1_BF, RIF_UNLOCK, RIF_SEC, RIF_PRIV, RIF_UNUSED, RIF_SEM_EN, RIF_CFEN)
		RIFPROT(RIF_RCC_RESOURCE(79), RIF_CID1_BF, RIF_UNLOCK, RIF_SEC, RIF_PRIV, RIF_UNUSED, RIF_SEM_EN, RIF_CFEN)
		RIFPROT(RIF_RCC_RESOURCE(80), RIF_UNUSED, RIF_UNLOCK, RIF_SEC, RIF_PRIV, RIF_CID1, RIF_SEM_DIS, RIF_CFEN)
		RIFPROT(RIF_RCC_RESOURCE(81), RIF_UNUSED, RIF_UNLOCK, RIF_SEC, RIF_PRIV, RIF_CID1, RIF_SEM_DIS, RIF_CFEN)
		RIFPROT(RIF_RCC_RESOURCE(82), RIF_UNUSED, RIF_UNLOCK, RIF_SEC, RIF_PRIV, RIF_CID1, RIF_SEM_DIS, RIF_CFEN)
		RIFPROT(RIF_RCC_RESOURCE(83), RIF_CID1_BF, RIF_UNLOCK, RIF_SEC, RIF_PRIV, RIF_UNUSED, RIF_SEM_EN, RIF_CFEN)
		RIFPROT(RIF_RCC_RESOURCE(84), RIF_CID1_BF, RIF_UNLOCK, RIF_SEC, RIF_PRIV, RIF_UNUSED, RIF_SEM_EN, RIF_CFEN)
		RIFPROT(RIF_RCC_RESOURCE(85), RIF_CID1_BF, RIF_UNLOCK, RIF_SEC, RIF_PRIV, RIF_UNUSED, RIF_SEM_EN, RIF_CFEN)
		RIFPROT(RIF_RCC_RESOURCE(86), RIF_CID1_BF, RIF_UNLOCK, RIF_SEC, RIF_PRIV, RIF_UNUSED, RIF_SEM_EN, RIF_CFEN)
		RIFPROT(RIF_RCC_RESOURCE(87), RIF_CID1_BF, RIF_UNLOCK, RIF_SEC, RIF_PRIV, RIF_UNUSED, RIF_SEM_EN, RIF_CFEN)
		RIFPROT(RIF_RCC_RESOURCE(88), RIF_CID1_BF, RIF_UNLOCK, RIF_SEC, RIF_PRIV, RIF_UNUSED, RIF_SEM_EN, RIF_CFEN)
		RIFPROT(RIF_RCC_RESOURCE(89), RIF_CID1_BF, RIF_UNLOCK, RIF_SEC, RIF_PRIV, RIF_UNUSED, RIF_SEM_EN, RIF_CFEN)
		RIFPROT(RIF_RCC_RESOURCE(90), RIF_CID1_BF, RIF_UNLOCK, RIF_SEC, RIF_PRIV, RIF_UNUSED, RIF_SEM_EN, RIF_CFEN)
		RIFPROT(RIF_RCC_RESOURCE(91), RIF_CID1_BF, RIF_UNLOCK, RIF_SEC, RIF_PRIV, RIF_UNUSED, RIF_SEM_EN, RIF_CFEN)
		RIFPROT(RIF_RCC_RESOURCE(92), RIF_CID1_BF, RIF_UNLOCK, RIF_SEC, RIF_PRIV, RIF_UNUSED, RIF_SEM_EN, RIF_CFEN)
		RIFPROT(RIF_RCC_RESOURCE(93), RIF_CID1_BF, RIF_UNLOCK, RIF_SEC, RIF_PRIV, RIF_UNUSED, RIF_SEM_EN, RIF_CFEN)
		RIFPROT(RIF_RCC_RESOURCE(94), RIF_CID1_BF, RIF_UNLOCK, RIF_SEC, RIF_PRIV, RIF_UNUSED, RIF_SEM_EN, RIF_CFEN)
		RIFPROT(RIF_RCC_RESOURCE(95), RIF_CID1_BF, RIF_UNLOCK, RIF_SEC, RIF_PRIV, RIF_UNUSED, RIF_SEM_EN, RIF_CFEN)
		RIFPROT(RIF_RCC_RESOURCE(96), RIF_CID1_BF, RIF_UNLOCK, RIF_SEC, RIF_PRIV, RIF_UNUSED, RIF_SEM_EN, RIF_CFEN)
		RIFPROT(RIF_RCC_RESOURCE(97), RIF_CID1_BF, RIF_UNLOCK, RIF_SEC, RIF_PRIV, RIF_UNUSED, RIF_SEM_EN, RIF_CFEN)
		RIFPROT(RIF_RCC_RESOURCE(98), RIF_CID1_BF, RIF_UNLOCK, RIF_SEC, RIF_PRIV, RIF_UNUSED, RIF_SEM_EN, RIF_CFEN)
		RIFPROT(RIF_RCC_RESOURCE(99), RIF_CID1_BF, RIF_UNLOCK, RIF_SEC, RIF_PRIV, RIF_UNUSED, RIF_SEM_EN, RIF_CFEN)
		RIFPROT(RIF_RCC_RESOURCE(100), RIF_CID1_BF, RIF_UNLOCK, RIF_SEC, RIF_PRIV, RIF_UNUSED, RIF_SEM_EN, RIF_CFEN)
		RIFPROT(RIF_RCC_RESOURCE(101), RIF_CID1_BF, RIF_UNLOCK, RIF_SEC, RIF_PRIV, RIF_UNUSED, RIF_SEM_EN, RIF_CFEN)
		RIFPROT(RIF_RCC_RESOURCE(102), RIF_UNUSED, RIF_UNLOCK, RIF_NSEC, RIF_NPRIV, RIF_UNUSED, RIF_SEM_DIS, RIF_CFDIS)
		RIFPROT(RIF_RCC_RESOURCE(103), RIF_UNUSED, RIF_UNLOCK, RIF_SEC, RIF_PRIV, RIF_CID1, RIF_SEM_DIS, RIF_CFEN)
		RIFPROT(RIF_RCC_RESOURCE(104), RIF_UNUSED, RIF_UNLOCK, RIF_NSEC, RIF_PRIV, RIF_CID1, RIF_SEM_DIS, RIF_CFEN)
		RIFPROT(RIF_RCC_RESOURCE(105), RIF_UNUSED, RIF_UNLOCK, RIF_SEC, RIF_PRIV, RIF_CID1, RIF_SEM_DIS, RIF_CFEN)
		RIFPROT(RIF_RCC_RESOURCE(106), RIF_UNUSED, RIF_UNLOCK, RIF_SEC, RIF_PRIV, RIF_CID1, RIF_SEM_DIS, RIF_CFEN)
		RIFPROT(RIF_RCC_RESOURCE(108), RIF_UNUSED, RIF_UNLOCK, RIF_SEC, RIF_PRIV, RIF_CID1, RIF_SEM_DIS, RIF_CFEN)
		RIFPROT(RIF_RCC_RESOURCE(109), RIF_UNUSED, RIF_UNLOCK, RIF_SEC, RIF_PRIV, RIF_CID1, RIF_SEM_DIS, RIF_CFEN)
		RIFPROT(RIF_RCC_RESOURCE(110), RIF_UNUSED, RIF_UNLOCK, RIF_NSEC, RIF_NPRIV, RIF_UNUSED, RIF_SEM_DIS, RIF_CFDIS)
		RIFPROT(RIF_RCC_RESOURCE(111), RIF_UNUSED, RIF_UNLOCK, RIF_NSEC, RIF_NPRIV, RIF_UNUSED, RIF_SEM_DIS, RIF_CFDIS)
		RIFPROT(RIF_RCC_RESOURCE(112), RIF_UNUSED, RIF_UNLOCK, RIF_SEC, RIF_PRIV, RIF_CID1, RIF_SEM_DIS, RIF_CFEN)
		RIFPROT(RIF_RCC_RESOURCE(113), RIF_UNUSED, RIF_UNLOCK, RIF_SEC, RIF_PRIV, RIF_CID1, RIF_SEM_DIS, RIF_CFEN)
		RIFPROT(RIF_RCC_RESOURCE(0), RIF_UNUSED, RIF_UNLOCK, RIF_SEC, RIF_PRIV, RIF_CID1, RIF_SEM_DIS, RIF_CFEN)
		RIFPROT(RIF_RCC_RESOURCE(1), RIF_UNUSED, RIF_UNLOCK, RIF_SEC, RIF_PRIV, RIF_CID1, RIF_SEM_DIS, RIF_CFEN)
		RIFPROT(RIF_RCC_RESOURCE(2), RIF_UNUSED, RIF_UNLOCK, RIF_SEC, RIF_PRIV, RIF_CID1, RIF_SEM_DIS, RIF_CFEN)
		RIFPROT(RIF_RCC_RESOURCE(3), RIF_UNUSED, RIF_UNLOCK, RIF_SEC, RIF_PRIV, RIF_CID1, RIF_SEM_DIS, RIF_CFEN)
		RIFPROT(RIF_RCC_RESOURCE(4), RIF_UNUSED, RIF_UNLOCK, RIF_SEC, RIF_PRIV, RIF_CID1, RIF_SEM_DIS, RIF_CFEN)
		RIFPROT(RIF_RCC_RESOURCE(5), RIF_UNUSED, RIF_UNLOCK, RIF_SEC, RIF_PRIV, RIF_CID1, RIF_SEM_DIS, RIF_CFEN)
		RIFPROT(RIF_RCC_RESOURCE(6), RIF_UNUSED, RIF_UNLOCK, RIF_SEC, RIF_PRIV, RIF_CID1, RIF_SEM_DIS, RIF_CFEN)
		RIFPROT(RIF_RCC_RESOURCE(7), RIF_UNUSED, RIF_UNLOCK, RIF_SEC, RIF_PRIV, RIF_CID1, RIF_SEM_DIS, RIF_CFEN)
		RIFPROT(RIF_RCC_RESOURCE(8), RIF_UNUSED, RIF_UNLOCK, RIF_SEC, RIF_PRIV, RIF_CID1, RIF_SEM_DIS, RIF_CFEN)
		RIFPROT(RIF_RCC_RESOURCE(9), RIF_UNUSED, RIF_UNLOCK, RIF_SEC, RIF_PRIV, RIF_CID1, RIF_SEM_DIS, RIF_CFEN)
		RIFPROT(RIF_RCC_RESOURCE(10), RIF_UNUSED, RIF_UNLOCK, RIF_SEC, RIF_PRIV, RIF_CID1, RIF_SEM_DIS, RIF_CFEN)
		RIFPROT(RIF_RCC_RESOURCE(11), RIF_UNUSED, RIF_UNLOCK, RIF_SEC, RIF_PRIV, RIF_CID1, RIF_SEM_DIS, RIF_CFEN)
		RIFPROT(RIF_RCC_RESOURCE(12), RIF_UNUSED, RIF_UNLOCK, RIF_SEC, RIF_PRIV, RIF_CID1, RIF_SEM_DIS, RIF_CFEN)
		RIFPROT(RIF_RCC_RESOURCE(13), RIF_UNUSED, RIF_UNLOCK, RIF_SEC, RIF_PRIV, RIF_CID1, RIF_SEM_DIS, RIF_CFEN)
		RIFPROT(RIF_RCC_RESOURCE(14), RIF_UNUSED, RIF_UNLOCK, RIF_SEC, RIF_PRIV, RIF_CID1, RIF_SEM_DIS, RIF_CFEN)
		RIFPROT(RIF_RCC_RESOURCE(15), RIF_UNUSED, RIF_UNLOCK, RIF_SEC, RIF_PRIV, RIF_CID1, RIF_SEM_DIS, RIF_CFEN)
		RIFPROT(RIF_RCC_RESOURCE(16), RIF_UNUSED, RIF_UNLOCK, RIF_SEC, RIF_PRIV, RIF_CID1, RIF_SEM_DIS, RIF_CFEN)
		RIFPROT(RIF_RCC_RESOURCE(17), RIF_UNUSED, RIF_UNLOCK, RIF_SEC, RIF_PRIV, RIF_CID1, RIF_SEM_DIS, RIF_CFEN)
		RIFPROT(RIF_RCC_RESOURCE(18), RIF_UNUSED, RIF_UNLOCK, RIF_SEC, RIF_PRIV, RIF_CID1, RIF_SEM_DIS, RIF_CFEN)
		RIFPROT(RIF_RCC_RESOURCE(19), RIF_UNUSED, RIF_UNLOCK, RIF_SEC, RIF_PRIV, RIF_CID1, RIF_SEM_DIS, RIF_CFEN)
		RIFPROT(RIF_RCC_RESOURCE(20), RIF_UNUSED, RIF_UNLOCK, RIF_SEC, RIF_PRIV, RIF_CID1, RIF_SEM_DIS, RIF_CFEN)
		RIFPROT(RIF_RCC_RESOURCE(21), RIF_UNUSED, RIF_UNLOCK, RIF_SEC, RIF_PRIV, RIF_CID1, RIF_SEM_DIS, RIF_CFEN)
		RIFPROT(RIF_RCC_RESOURCE(22), RIF_UNUSED, RIF_UNLOCK, RIF_SEC, RIF_PRIV, RIF_CID1, RIF_SEM_DIS, RIF_CFEN)
		RIFPROT(RIF_RCC_RESOURCE(23), RIF_UNUSED, RIF_UNLOCK, RIF_SEC, RIF_PRIV, RIF_CID1, RIF_SEM_DIS, RIF_CFEN)
		RIFPROT(RIF_RCC_RESOURCE(24), RIF_UNUSED, RIF_UNLOCK, RIF_SEC, RIF_PRIV, RIF_CID1, RIF_SEM_DIS, RIF_CFEN)
		RIFPROT(RIF_RCC_RESOURCE(25), RIF_UNUSED, RIF_UNLOCK, RIF_SEC, RIF_PRIV, RIF_CID1, RIF_SEM_DIS, RIF_CFEN)
		RIFPROT(RIF_RCC_RESOURCE(26), RIF_UNUSED, RIF_UNLOCK, RIF_SEC, RIF_PRIV, RIF_CID1, RIF_SEM_DIS, RIF_CFEN)
		RIFPROT(RIF_RCC_RESOURCE(27), RIF_UNUSED, RIF_UNLOCK, RIF_SEC, RIF_PRIV, RIF_CID1, RIF_SEM_DIS, RIF_CFEN)
		RIFPROT(RIF_RCC_RESOURCE(28), RIF_UNUSED, RIF_UNLOCK, RIF_SEC, RIF_PRIV, RIF_CID1, RIF_SEM_DIS, RIF_CFEN)
		RIFPROT(RIF_RCC_RESOURCE(29), RIF_UNUSED, RIF_UNLOCK, RIF_SEC, RIF_PRIV, RIF_CID1, RIF_SEM_DIS, RIF_CFEN)
		RIFPROT(RIF_RCC_RESOURCE(30), RIF_UNUSED, RIF_UNLOCK, RIF_SEC, RIF_PRIV, RIF_CID1, RIF_SEM_DIS, RIF_CFEN)
		RIFPROT(RIF_RCC_RESOURCE(31), RIF_UNUSED, RIF_UNLOCK, RIF_SEC, RIF_PRIV, RIF_CID1, RIF_SEM_DIS, RIF_CFEN)
		RIFPROT(RIF_RCC_RESOURCE(32), RIF_UNUSED, RIF_UNLOCK, RIF_SEC, RIF_PRIV, RIF_CID1, RIF_SEM_DIS, RIF_CFEN)
		RIFPROT(RIF_RCC_RESOURCE(33), RIF_UNUSED, RIF_UNLOCK, RIF_SEC, RIF_PRIV, RIF_CID1, RIF_SEM_DIS, RIF_CFEN)
		RIFPROT(RIF_RCC_RESOURCE(34), RIF_UNUSED, RIF_UNLOCK, RIF_SEC, RIF_PRIV, RIF_CID1, RIF_SEM_DIS, RIF_CFEN)
		RIFPROT(RIF_RCC_RESOURCE(35), RIF_UNUSED, RIF_UNLOCK, RIF_SEC, RIF_PRIV, RIF_CID1, RIF_SEM_DIS, RIF_CFEN)
		RIFPROT(RIF_RCC_RESOURCE(36), RIF_UNUSED, RIF_UNLOCK, RIF_SEC, RIF_PRIV, RIF_CID1, RIF_SEM_DIS, RIF_CFEN)
		RIFPROT(RIF_RCC_RESOURCE(37), RIF_UNUSED, RIF_UNLOCK, RIF_SEC, RIF_PRIV, RIF_CID1, RIF_SEM_DIS, RIF_CFEN)
		RIFPROT(RIF_RCC_RESOURCE(38), RIF_UNUSED, RIF_UNLOCK, RIF_SEC, RIF_PRIV, RIF_CID1, RIF_SEM_DIS, RIF_CFEN)
		RIFPROT(RIF_RCC_RESOURCE(39), RIF_UNUSED, RIF_UNLOCK, RIF_SEC, RIF_PRIV, RIF_CID1, RIF_SEM_DIS, RIF_CFEN)
		RIFPROT(RIF_RCC_RESOURCE(40), RIF_UNUSED, RIF_UNLOCK, RIF_SEC, RIF_PRIV, RIF_CID1, RIF_SEM_DIS, RIF_CFEN)
		RIFPROT(RIF_RCC_RESOURCE(41), RIF_UNUSED, RIF_UNLOCK, RIF_SEC, RIF_PRIV, RIF_CID1, RIF_SEM_DIS, RIF_CFEN)
		RIFPROT(RIF_RCC_RESOURCE(42), RIF_UNUSED, RIF_UNLOCK, RIF_SEC, RIF_PRIV, RIF_CID1, RIF_SEM_DIS, RIF_CFEN)
		RIFPROT(RIF_RCC_RESOURCE(43), RIF_UNUSED, RIF_UNLOCK, RIF_SEC, RIF_PRIV, RIF_CID1, RIF_SEM_DIS, RIF_CFEN)
		RIFPROT(RIF_RCC_RESOURCE(44), RIF_UNUSED, RIF_UNLOCK, RIF_SEC, RIF_PRIV, RIF_CID1, RIF_SEM_DIS, RIF_CFEN)
		RIFPROT(RIF_RCC_RESOURCE(45), RIF_UNUSED, RIF_UNLOCK, RIF_SEC, RIF_PRIV, RIF_CID1, RIF_SEM_DIS, RIF_CFEN)
		RIFPROT(RIF_RCC_RESOURCE(46), RIF_UNUSED, RIF_UNLOCK, RIF_SEC, RIF_PRIV, RIF_CID1, RIF_SEM_DIS, RIF_CFEN)
		RIFPROT(RIF_RCC_RESOURCE(47), RIF_UNUSED, RIF_UNLOCK, RIF_SEC, RIF_PRIV, RIF_CID1, RIF_SEM_DIS, RIF_CFEN)
		RIFPROT(RIF_RCC_RESOURCE(48), RIF_UNUSED, RIF_UNLOCK, RIF_SEC, RIF_PRIV, RIF_CID1, RIF_SEM_DIS, RIF_CFEN)
		RIFPROT(RIF_RCC_RESOURCE(49), RIF_UNUSED, RIF_UNLOCK, RIF_SEC, RIF_PRIV, RIF_CID1, RIF_SEM_DIS, RIF_CFEN)
		RIFPROT(RIF_RCC_RESOURCE(50), EMPTY_SEMWL, RIF_UNLOCK, RIF_NSEC, RIF_PRIV, RIF_UNUSED, RIF_SEM_EN, RIF_CFEN)
		RIFPROT(RIF_RCC_RESOURCE(51), RIF_UNUSED, RIF_UNLOCK, RIF_SEC, RIF_PRIV, RIF_CID1, RIF_SEM_DIS, RIF_CFEN)
		RIFPROT(RIF_RCC_RESOURCE(52), RIF_UNUSED, RIF_UNLOCK, RIF_SEC, RIF_PRIV, RIF_CID1, RIF_SEM_DIS, RIF_CFEN)
		RIFPROT(RIF_RCC_RESOURCE(53), RIF_UNUSED, RIF_UNLOCK, RIF_SEC, RIF_PRIV, RIF_CID1, RIF_SEM_DIS, RIF_CFEN)
		RIFPROT(RIF_RCC_RESOURCE(54), RIF_UNUSED, RIF_UNLOCK, RIF_SEC, RIF_PRIV, RIF_CID1, RIF_SEM_DIS, RIF_CFEN)
		RIFPROT(RIF_RCC_RESOURCE(55), RIF_UNUSED, RIF_UNLOCK, RIF_SEC, RIF_PRIV, RIF_CID1, RIF_SEM_DIS, RIF_CFEN)
		RIFPROT(RIF_RCC_RESOURCE(56), RIF_UNUSED, RIF_UNLOCK, RIF_SEC, RIF_PRIV, RIF_CID1, RIF_SEM_DIS, RIF_CFEN)
		RIFPROT(RIF_RCC_RESOURCE(57), RIF_UNUSED, RIF_UNLOCK, RIF_SEC, RIF_PRIV, RIF_CID1, RIF_SEM_DIS, RIF_CFEN)
		RIFPROT(RIF_RCC_RESOURCE(58), RIF_UNUSED, RIF_UNLOCK, RIF_SEC, RIF_PRIV, RIF_CID1, RIF_SEM_DIS, RIF_CFEN)
		RIFPROT(RIF_RCC_RESOURCE(59), RIF_UNUSED, RIF_UNLOCK, RIF_SEC, RIF_PRIV, RIF_CID1, RIF_SEM_DIS, RIF_CFEN)
		RIFPROT(RIF_RCC_RESOURCE(60), RIF_UNUSED, RIF_UNLOCK, RIF_SEC, RIF_PRIV, RIF_CID1, RIF_SEM_DIS, RIF_CFEN)
		RIFPROT(RIF_RCC_RESOURCE(61), RIF_UNUSED, RIF_UNLOCK, RIF_SEC, RIF_PRIV, RIF_CID1, RIF_SEM_DIS, RIF_CFEN)
		RIFPROT(RIF_RCC_RESOURCE(62), RIF_UNUSED, RIF_UNLOCK, RIF_SEC, RIF_PRIV, RIF_CID1, RIF_SEM_DIS, RIF_CFEN)
		RIFPROT(RIF_RCC_RESOURCE(63), RIF_UNUSED, RIF_UNLOCK, RIF_SEC, RIF_PRIV, RIF_CID1, RIF_SEM_DIS, RIF_CFEN)
	>;
};

&ipcc1 {
	st,protreg = <
		RIFPROT(RIF_IPCC_CPU1_CHANNEL(1), RIF_UNUSED, RIF_UNLOCK, RIF_NSEC, RIF_NPRIV, RIF_CID1, RIF_SEM_DIS, RIF_CFEN)
		RIFPROT(RIF_IPCC_CPU2_CHANNEL(1), RIF_UNUSED, RIF_UNLOCK, RIF_NSEC, RIF_NPRIV, RIF_CID2, RIF_SEM_DIS, RIF_CFEN)
		RIFPROT(RIF_IPCC_CPU1_CHANNEL(2), RIF_UNUSED, RIF_UNLOCK, RIF_NSEC, RIF_NPRIV, RIF_CID1, RIF_SEM_DIS, RIF_CFEN)
		RIFPROT(RIF_IPCC_CPU2_CHANNEL(2), RIF_UNUSED, RIF_UNLOCK, RIF_NSEC, RIF_NPRIV, RIF_CID2, RIF_SEM_DIS, RIF_CFEN)
		RIFPROT(RIF_IPCC_CPU1_CHANNEL(3), RIF_UNUSED, RIF_UNLOCK, RIF_NSEC, RIF_NPRIV, RIF_CID1, RIF_SEM_DIS, RIF_CFEN)
		RIFPROT(RIF_IPCC_CPU2_CHANNEL(3), RIF_UNUSED, RIF_UNLOCK, RIF_NSEC, RIF_NPRIV, RIF_CID2, RIF_SEM_DIS, RIF_CFEN)
		RIFPROT(RIF_IPCC_CPU1_CHANNEL(4), RIF_UNUSED, RIF_UNLOCK, RIF_NSEC, RIF_NPRIV, RIF_CID1, RIF_SEM_DIS, RIF_CFEN)
		RIFPROT(RIF_IPCC_CPU2_CHANNEL(4), RIF_UNUSED, RIF_UNLOCK, RIF_NSEC, RIF_NPRIV, RIF_CID2, RIF_SEM_DIS, RIF_CFEN)
		RIFPROT(RIF_IPCC_CPU1_CHANNEL(5), RIF_UNUSED, RIF_UNLOCK, RIF_NSEC, RIF_NPRIV, RIF_CID1, RIF_SEM_DIS, RIF_CFEN)
		RIFPROT(RIF_IPCC_CPU2_CHANNEL(5), RIF_UNUSED, RIF_UNLOCK, RIF_NSEC, RIF_NPRIV, RIF_CID2, RIF_SEM_DIS, RIF_CFEN)
		RIFPROT(RIF_IPCC_CPU1_CHANNEL(6), RIF_UNUSED, RIF_UNLOCK, RIF_NSEC, RIF_NPRIV, RIF_CID1, RIF_SEM_DIS, RIF_CFEN)
		RIFPROT(RIF_IPCC_CPU2_CHANNEL(6), RIF_UNUSED, RIF_UNLOCK, RIF_NSEC, RIF_NPRIV, RIF_CID2, RIF_SEM_DIS, RIF_CFEN)
		RIFPROT(RIF_IPCC_CPU1_CHANNEL(7), RIF_UNUSED, RIF_UNLOCK, RIF_NSEC, RIF_NPRIV, RIF_CID1, RIF_SEM_DIS, RIF_CFEN)
		RIFPROT(RIF_IPCC_CPU2_CHANNEL(7), RIF_UNUSED, RIF_UNLOCK, RIF_NSEC, RIF_NPRIV, RIF_CID2, RIF_SEM_DIS, RIF_CFEN)
		RIFPROT(RIF_IPCC_CPU1_CHANNEL(8), RIF_UNUSED, RIF_UNLOCK, RIF_NSEC, RIF_NPRIV, RIF_CID1, RIF_SEM_DIS, RIF_CFEN)
		RIFPROT(RIF_IPCC_CPU2_CHANNEL(8), RIF_UNUSED, RIF_UNLOCK, RIF_NSEC, RIF_NPRIV, RIF_CID2, RIF_SEM_DIS, RIF_CFEN)
		RIFPROT(RIF_IPCC_CPU1_CHANNEL(9), RIF_UNUSED, RIF_UNLOCK, RIF_NSEC, RIF_NPRIV, RIF_CID1, RIF_SEM_DIS, RIF_CFEN)
		RIFPROT(RIF_IPCC_CPU2_CHANNEL(9), RIF_UNUSED, RIF_UNLOCK, RIF_NSEC, RIF_NPRIV, RIF_CID2, RIF_SEM_DIS, RIF_CFEN)
		RIFPROT(RIF_IPCC_CPU1_CHANNEL(10), RIF_UNUSED, RIF_UNLOCK, RIF_NSEC, RIF_NPRIV, RIF_CID1, RIF_SEM_DIS, RIF_CFEN)
		RIFPROT(RIF_IPCC_CPU2_CHANNEL(10), RIF_UNUSED, RIF_UNLOCK, RIF_NSEC, RIF_NPRIV, RIF_CID2, RIF_SEM_DIS, RIF_CFEN)
		RIFPROT(RIF_IPCC_CPU1_CHANNEL(11), RIF_UNUSED, RIF_UNLOCK, RIF_NSEC, RIF_NPRIV, RIF_CID1, RIF_SEM_DIS, RIF_CFEN)
		RIFPROT(RIF_IPCC_CPU2_CHANNEL(11), RIF_UNUSED, RIF_UNLOCK, RIF_NSEC, RIF_NPRIV, RIF_CID2, RIF_SEM_DIS, RIF_CFEN)
		RIFPROT(RIF_IPCC_CPU1_CHANNEL(12), RIF_UNUSED, RIF_UNLOCK, RIF_NSEC, RIF_NPRIV, RIF_CID1, RIF_SEM_DIS, RIF_CFEN)
		RIFPROT(RIF_IPCC_CPU2_CHANNEL(12), RIF_UNUSED, RIF_UNLOCK, RIF_NSEC, RIF_NPRIV, RIF_CID2, RIF_SEM_DIS, RIF_CFEN)
		RIFPROT(RIF_IPCC_CPU1_CHANNEL(13), RIF_UNUSED, RIF_UNLOCK, RIF_SEC, RIF_PRIV, RIF_CID1, RIF_SEM_DIS, RIF_CFEN)
		RIFPROT(RIF_IPCC_CPU2_CHANNEL(13), RIF_UNUSED, RIF_UNLOCK, RIF_NSEC, RIF_NPRIV, RIF_CID2, RIF_SEM_DIS, RIF_CFEN)
		RIFPROT(RIF_IPCC_CPU1_CHANNEL(14), RIF_UNUSED, RIF_UNLOCK, RIF_SEC, RIF_PRIV, RIF_CID1, RIF_SEM_DIS, RIF_CFEN)
		RIFPROT(RIF_IPCC_CPU2_CHANNEL(14), RIF_UNUSED, RIF_UNLOCK, RIF_NSEC, RIF_NPRIV, RIF_CID2, RIF_SEM_DIS, RIF_CFEN)
		RIFPROT(RIF_IPCC_CPU1_CHANNEL(15), RIF_UNUSED, RIF_UNLOCK, RIF_SEC, RIF_PRIV, RIF_CID1, RIF_SEM_DIS, RIF_CFEN)
		RIFPROT(RIF_IPCC_CPU2_CHANNEL(15), RIF_UNUSED, RIF_UNLOCK, RIF_NSEC, RIF_NPRIV, RIF_CID2, RIF_SEM_DIS, RIF_CFEN)
		RIFPROT(RIF_IPCC_CPU1_CHANNEL(16), RIF_UNUSED, RIF_UNLOCK, RIF_SEC, RIF_PRIV, RIF_CID1, RIF_SEM_DIS, RIF_CFEN)
		RIFPROT(RIF_IPCC_CPU2_CHANNEL(16), RIF_UNUSED, RIF_UNLOCK, RIF_NSEC, RIF_NPRIV, RIF_CID2, RIF_SEM_DIS, RIF_CFEN)
	>;
};

&ipcc2 {
	st,protreg = <
		RIFPROT(RIF_IPCC_CPU1_CHANNEL(1), RIF_UNUSED, RIF_UNLOCK, RIF_NSEC, RIF_NPRIV, RIF_CID3, RIF_SEM_DIS, RIF_CFEN)
		RIFPROT(RIF_IPCC_CPU2_CHANNEL(1), RIF_UNUSED, RIF_UNLOCK, RIF_NSEC, RIF_NPRIV, RIF_CID1, RIF_SEM_DIS, RIF_CFEN)
		RIFPROT(RIF_IPCC_CPU1_CHANNEL(2), RIF_UNUSED, RIF_UNLOCK, RIF_NSEC, RIF_NPRIV, RIF_CID3, RIF_SEM_DIS, RIF_CFEN)
		RIFPROT(RIF_IPCC_CPU2_CHANNEL(2), RIF_UNUSED, RIF_UNLOCK, RIF_NSEC, RIF_NPRIV, RIF_CID1, RIF_SEM_DIS, RIF_CFEN)
		RIFPROT(RIF_IPCC_CPU1_CHANNEL(3), RIF_UNUSED, RIF_UNLOCK, RIF_NSEC, RIF_NPRIV, RIF_CID3, RIF_SEM_DIS, RIF_CFEN)
		RIFPROT(RIF_IPCC_CPU2_CHANNEL(3), RIF_UNUSED, RIF_UNLOCK, RIF_NSEC, RIF_NPRIV, RIF_CID1, RIF_SEM_DIS, RIF_CFEN)
		RIFPROT(RIF_IPCC_CPU1_CHANNEL(4), RIF_UNUSED, RIF_UNLOCK, RIF_NSEC, RIF_NPRIV, RIF_CID3, RIF_SEM_DIS, RIF_CFEN)
		RIFPROT(RIF_IPCC_CPU2_CHANNEL(4), RIF_UNUSED, RIF_UNLOCK, RIF_NSEC, RIF_NPRIV, RIF_CID1, RIF_SEM_DIS, RIF_CFEN)
	>;
};

&hsem {
	st,proccid = <1 RIF_CID1>, <2 RIF_CID2>, <3 RIF_CID3>;
	st,protreg = <
		RIFPROT(RIF_HSEM_RESOURCE(0), RIF_UNUSED, RIF_UNLOCK, RIF_NSEC, RIF_NPRIV, RIF_UNUSED, RIF_SEM_DIS, RIF_CFDIS)
		RIFPROT(RIF_HSEM_RESOURCE(1), RIF_UNUSED, RIF_UNLOCK, RIF_NSEC, RIF_NPRIV, RIF_UNUSED, RIF_SEM_DIS, RIF_CFDIS)
		RIFPROT(RIF_HSEM_RESOURCE(2), RIF_UNUSED, RIF_UNLOCK, RIF_NSEC, RIF_NPRIV, RIF_UNUSED, RIF_SEM_DIS, RIF_CFDIS)
		RIFPROT(RIF_HSEM_RESOURCE(3), RIF_UNUSED, RIF_UNLOCK, RIF_NSEC, RIF_NPRIV, RIF_UNUSED, RIF_SEM_DIS, RIF_CFDIS)
		RIFPROT(RIF_HSEM_RESOURCE(4), RIF_UNUSED, RIF_UNLOCK, RIF_NSEC, RIF_NPRIV, RIF_UNUSED, RIF_SEM_DIS, RIF_CFDIS)
		RIFPROT(RIF_HSEM_RESOURCE(5), RIF_UNUSED, RIF_UNLOCK, RIF_NSEC, RIF_NPRIV, RIF_UNUSED, RIF_SEM_DIS, RIF_CFDIS)
		RIFPROT(RIF_HSEM_RESOURCE(6), RIF_UNUSED, RIF_UNLOCK, RIF_NSEC, RIF_NPRIV, RIF_UNUSED, RIF_SEM_DIS, RIF_CFDIS)
		RIFPROT(RIF_HSEM_RESOURCE(7), RIF_UNUSED, RIF_UNLOCK, RIF_NSEC, RIF_NPRIV, RIF_UNUSED, RIF_SEM_DIS, RIF_CFDIS)
		RIFPROT(RIF_HSEM_RESOURCE(8), RIF_UNUSED, RIF_UNLOCK, RIF_NSEC, RIF_NPRIV, RIF_UNUSED, RIF_SEM_DIS, RIF_CFDIS)
		RIFPROT(RIF_HSEM_RESOURCE(9), RIF_UNUSED, RIF_UNLOCK, RIF_NSEC, RIF_NPRIV, RIF_UNUSED, RIF_SEM_DIS, RIF_CFDIS)
		RIFPROT(RIF_HSEM_RESOURCE(10), RIF_UNUSED, RIF_UNLOCK, RIF_NSEC, RIF_NPRIV, RIF_UNUSED, RIF_SEM_DIS, RIF_CFDIS)
		RIFPROT(RIF_HSEM_RESOURCE(11), RIF_UNUSED, RIF_UNLOCK, RIF_NSEC, RIF_NPRIV, RIF_UNUSED, RIF_SEM_DIS, RIF_CFDIS)
		RIFPROT(RIF_HSEM_RESOURCE(12), RIF_UNUSED, RIF_UNLOCK, RIF_NSEC, RIF_NPRIV, RIF_UNUSED, RIF_SEM_DIS, RIF_CFDIS)
		RIFPROT(RIF_HSEM_RESOURCE(13), RIF_UNUSED, RIF_UNLOCK, RIF_NSEC, RIF_NPRIV, RIF_UNUSED, RIF_SEM_DIS, RIF_CFDIS)
		RIFPROT(RIF_HSEM_RESOURCE(14), RIF_UNUSED, RIF_UNLOCK, RIF_NSEC, RIF_NPRIV, RIF_UNUSED, RIF_SEM_DIS, RIF_CFDIS)
		RIFPROT(RIF_HSEM_RESOURCE(15), RIF_UNUSED, RIF_UNLOCK, RIF_NSEC, RIF_NPRIV, RIF_UNUSED, RIF_SEM_DIS, RIF_CFDIS)
	>;
};

&tfa_bl31 {
	st,protreg = <RISABPROT(RIF_DDCID_DIS, RIF_UNUSED, RIF_SEC, RIF_UNUSED, RIF_CFEN, RIF_CID1_BF, RIF_CID1_BF, RIF_CID1_BF)>;
};

&hpdma_lli {
	st,protreg = <RISABPROT(RIF_DDCID_DIS, RIF_UNUSED, RIF_NSEC, RIF_PRIV, RIF_CFDIS, RIF_UNUSED, RIF_UNUSED, RIF_UNUSED)>;
};

&bsec_mirror {
	st,protreg = <RISABPROT(RIF_DDCID_DIS, RIF_UNUSED, RIF_SEC, RIF_NPRIV, RIF_CFDIS, RIF_UNUSED, RIF_UNUSED, RIF_UNUSED)>;
};

&cm33_sram1 {
	st,protreg = <RISABPROT(RIF_DDCID_DIS, RIF_UNUSED, RIF_NSEC, RIF_NPRIV, RIF_CFDIS, RIF_UNUSED, RIF_UNUSED, RIF_UNUSED)>;
};

&cm33_sram2 {
	st,protreg = <RISABPROT(RIF_DDCID_DIS, RIF_UNUSED, RIF_NSEC, RIF_NPRIV, RIF_CFDIS, RIF_UNUSED, RIF_UNUSED, RIF_UNUSED)>;
};

&cm33_retram {
	st,protreg = <RISABPROT(RIF_DDCID_DIS, RIF_UNUSED, RIF_SEC, RIF_NPRIV, RIF_CFDIS, RIF_UNUSED, RIF_UNUSED, RIF_UNUSED)>;
};

&ddr_param {
	st,protreg = <RISABPROT(RIF_DDCID_DIS, RIF_UNUSED, RIF_SEC, RIF_NPRIV, RIF_CFDIS, RIF_UNUSED, RIF_UNUSED, RIF_UNUSED)>;
};

&risab1 {
	memory-region = <&tfa_bl31>;
};

&risab2 {
	memory-region = <&hpdma_lli>;
};

&risab3 {
	st,srwiad;
	memory-region = <&bsec_mirror>, <&cm33_sram1>;
};

&risab4 {
	st,srwiad;
	memory-region = <&cm33_sram2>;
};

&risab5 {
	st,srwiad;
	memory-region = <&cm33_retram>, <&ddr_param>;
};

&mm_ospi1 {
	st,protreg = <RISAFPROT(RISAF_REG_ID(1), RIF_CID1_BF | RIF_CID2_BF, RIF_CID1_BF | RIF_CID2_BF, 0, RIF_NSEC, RIF_ENC_DIS, RIF_BREN_EN)>;
};

&risaf2 {
	memory-region = <&mm_ospi1>;
};

&pcie_device {
	st,protreg = <RISAFPROT(RISAF_REG_ID(1), RIF_CID0_BF|RIF_CID1_BF, RIF_CID0_BF|RIF_CID1_BF, RIF_UNUSED, RIF_NSEC, RIF_ENC_DIS, RIF_BREN_EN)>;
};

&risaf5 {
	memory-region = <&pcie_device>;
};

&bl31_lowpower {
	st,protreg = <RISAFPROT(RISAF_REG_ID(1), RIF_CID0_BF|RIF_CID1_BF, RIF_CID0_BF|RIF_CID1_BF, RIF_CID1_BF, RIF_SEC, RIF_ENC_DIS, RIF_BREN_EN)>;
};

&tfm_its {
	st,protreg = <RISAFPROT(RISAF_REG_ID(2), RIF_CID2_BF, RIF_CID2_BF, RIF_CID2_BF, RIF_SEC, RIF_ENC_DIS, RIF_BREN_EN)>;
};

&risaf1 {
	memory-region = <&bl31_lowpower>, <&tfm_its>;
};

&tfm_code {
	st,protreg = <RISAFPROT(RISAF_REG_ID(1), RIF_CID2_BF, RIF_CID2_BF, RIF_UNUSED, RIF_SEC, RIF_ENC_EN, RIF_BREN_EN)>;
};

&cm33_cube_fw {
	st,protreg = <RISAFPROT(RISAF_REG_ID(2), RIF_CID0_BF|RIF_CID1_BF|RIF_CID2_BF, RIF_CID0_BF|RIF_CID1_BF|RIF_CID2_BF, RIF_UNUSED, RIF_NSEC, RIF_ENC_DIS, RIF_BREN_EN)>;
};

&tfm_data {
	st,protreg = <RISAFPROT(RISAF_REG_ID(3), RIF_CID2_BF, RIF_CID2_BF, RIF_UNUSED, RIF_SEC, RIF_ENC_EN, RIF_BREN_EN)>;
};

&cm33_cube_data {
	st,protreg = <RISAFPROT(RISAF_REG_ID(4), RIF_CID0_BF|RIF_CID1_BF|RIF_CID2_BF, RIF_CID0_BF|RIF_CID1_BF|RIF_CID2_BF, RIF_UNUSED, RIF_NSEC, RIF_ENC_DIS, RIF_BREN_EN)>;
};

&ipc_shmem {
	st,protreg = <RISAFPROT(RISAF_REG_ID(5), RIF_CID0_BF|RIF_CID1_BF|RIF_CID2_BF, RIF_CID0_BF|RIF_CID1_BF|RIF_CID2_BF, RIF_UNUSED, RIF_NSEC, RIF_ENC_DIS, RIF_BREN_EN)>;
};

&spare1 {
	st,protreg = <RISAFPROT(RISAF_REG_ID(6), RIF_CID0_BF|RIF_CID1_BF|RIF_CID2_BF, RIF_CID0_BF|RIF_CID1_BF|RIF_CID2_BF, RIF_UNUSED, RIF_NSEC, RIF_ENC_DIS, RIF_BREN_EN)>;
};

&bl31_context {
	st,protreg = <RISAFPROT(RISAF_REG_ID(7), RIF_CID0_BF|RIF_CID1_BF, RIF_CID0_BF|RIF_CID1_BF, RIF_UNUSED, RIF_SEC, RIF_ENC_EN, RIF_BREN_EN)>;
};

&op_tee {
	st,protreg = <RISAFPROT(RISAF_REG_ID(8), RIF_CID0_BF|RIF_CID1_BF, RIF_CID0_BF|RIF_CID1_BF, RIF_UNUSED, RIF_SEC, RIF_ENC_EN, RIF_BREN_EN)>;
};

&linuxkernel1 {
	st,protreg = <RISAFPROT(RISAF_REG_ID(9), RIF_CID0_BF|RIF_CID1_BF, RIF_CID0_BF|RIF_CID1_BF, RIF_UNUSED, RIF_NSEC, RIF_ENC_DIS, RIF_BREN_EN)>;
};

&gpu_reserved {
	st,protreg = <RISAFPROT(RISAF_REG_ID(10), RIF_CID0_BF|RIF_CID1_BF, RIF_CID0_BF|RIF_CID1_BF, RIF_UNUSED, RIF_NSEC, RIF_ENC_DIS, RIF_BREN_EN)>;
};

&ltdc_sec_layer {
	st,protreg = <RISAFPROT(RISAF_REG_ID(13), RIF_CID0_BF|RIF_CID1_BF, RIF_CID0_BF|RIF_CID1_BF, RIF_UNUSED, RIF_NSEC, RIF_ENC_DIS, RIF_BREN_EN)>;
};

&ltdc_sec_rotation {
	st,protreg = <RISAFPROT(RISAF_REG_ID(14), RIF_CID0_BF|RIF_CID1_BF, RIF_CID0_BF|RIF_CID1_BF, RIF_UNUSED, RIF_NSEC, RIF_ENC_DIS, RIF_BREN_EN)>;
};

&linuxkernel2 {
	st,protreg = <RISAFPROT(RISAF_REG_ID(15), RIF_CID0_BF|RIF_CID1_BF, RIF_CID0_BF|RIF_CID1_BF, RIF_UNUSED, RIF_NSEC, RIF_ENC_DIS, RIF_BREN_EN)>;
};

&risaf4 {
	memory-region = <&tfm_code>, <&cm33_cube_fw>, <&tfm_data>, <&cm33_cube_data>, <&ipc_shmem>, <&spare1>, <&bl31_context>, <&op_tee>, <&linuxkernel1>, <&gpu_reserved>, <&ltdc_sec_layer>, <&ltdc_sec_rotation>, <&linuxkernel2>;
};
